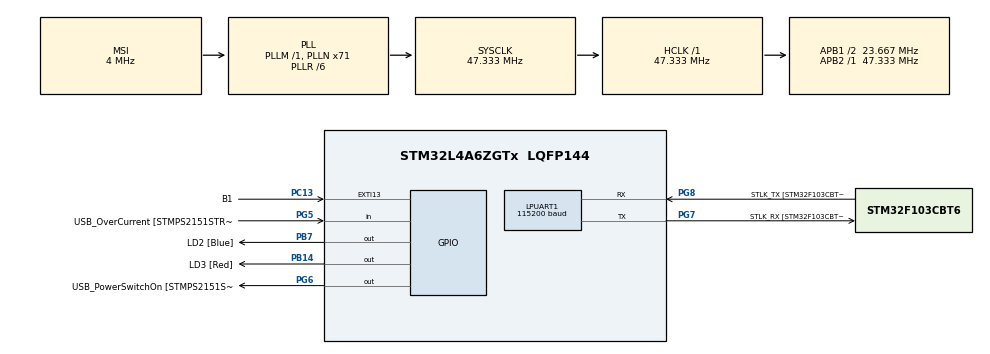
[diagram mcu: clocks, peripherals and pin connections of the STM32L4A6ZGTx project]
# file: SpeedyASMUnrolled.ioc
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LPUART1.AutoBaudRateEnableParam=UART_ADVFEATURE_AUTOBAUDRATE_DISABLE
LPUART1.BaudRate=115200
LPUART1.DMADisableonRxErrorParam=UART_ADVFEATURE_DMA_ENABLEONRXERROR
LPUART1.DataInvertParam=UART_ADVFEATURE_DATAINV_DISABLE
LPUART1.MSBFirstParam=UART_ADVFEATURE_MSBFIRST_DISABLE
LPUART1.Mode=UART_MODE_TX_RX
LPUART1.OneBitSampling=UART_ONE_BIT_SAMPLE_DISABLE
LPUART1.OverrunDisableParam=UART_ADVFEATURE_OVERRUN_ENABLE
LPUART1.Parity=UART_PARITY_NONE
LPUART1.RxPinLevelInvertParam=UART_ADVFEATURE_RXINV_DISABLE
LPUART1.StopBits=UART_STOPBITS_1
LPUART1.SwapParam=UART_ADVFEATURE_SWAP_DISABLE
LPUART1.TxPinLevelInvertParam=UART_ADVFEATURE_TXINV_DISABLE
LPUART1.WordLength=UART_WORDLENGTH_8B
Mcu.Family=STM32L4
Mcu.Name=STM32L4A6ZGTx
Mcu.Package=LQFP144
NVIC.PriorityGroup=NVIC_PRIORITYGROUP_4
PA10.GPIO_Label=USB_ID
PA10.Signal=USB_OTG_FS_ID
PA11.GPIO_Label=USB_DM
PA11.Signal=USB_OTG_FS_DM
PA12.GPIO_Label=USB_DP
PA12.Signal=USB_OTG_FS_DP
PA13\ (JTMS/SWDIO).GPIO_Label=TMS
PA13\ (JTMS/SWDIO).Mode=Trace_Asynchronous_SW
PA13\ (JTMS/SWDIO).Signal=SYS_JTMS-SWDIO
PA14\ (JTCK/SWCLK).GPIO_Label=TCK
PA14\ (JTCK/SWCLK).Mode=Trace_Asynchronous_SW
PA14\ (JTCK/SWCLK).Signal=SYS_JTCK-SWCLK
PA8.GPIO_Label=USB_SOF [TP1]
PA8.Signal=USB_OTG_FS_SOF
PA9.GPIO_Label=USB_VBUS
PA9.Signal=USB_OTG_FS_VBUS
PB14.GPIO_Label=LD3 [Red]
PB14.Signal=GPIO_Output
PB3\ (JTDO/TRACESWO).GPIO_Label=SWO
PB3\ (JTDO/TRACESWO).Mode=Trace_Asynchronous_SW
PB3\ (JTDO/TRACESWO).Signal=SYS_JTDO-SWO
PB7.GPIO_Label=LD2 [Blue]
PB7.Signal=GPIO_Output
PC13.GPIO_Label=B1
PC13.Signal=GPXTI13
PC14-OSC32_IN\ (PC14).Mode=LSE-External-Oscillator
PC14-OSC32_IN\ (PC14).Signal=RCC_OSC32_IN
PC15-OSC32_OUT\ (PC15).Mode=LSE-External-Oscillator
PC15-OSC32_OUT\ (PC15).Signal=RCC_OSC32_OUT
PG5.GPIO_Label=USB_OverCurrent [STMPS2151STR_FAULT]
PG5.Signal=GPIO_Input
PG6.GPIO_Label=USB_PowerSwitchOn [STMPS2151STR_EN]
PG6.Signal=GPIO_Output
PG7.GPIO_Label=STLK_RX [STM32F103CBT6_PA3]
PG7.Mode=Asynchronous
PG7.Signal=LPUART1_TX
PG8.GPIO_Label=STLK_TX [STM32F103CBT6_PA2]
PG8.Mode=Asynchronous
PG8.Signal=LPUART1_RX
PH1-OSC_OUT\ (PH1).Signal=RCC_OSC_OUT
ProjectManager.HeapSize=0x200
ProjectManager.StackSize=0x400
ProjectManager.TargetToolchain=STM32CubeIDE
RCC.ADCFreq_Value=48000000
RCC.AHBFreq_Value=47333333.333333336
RCC.APB1CLKDivider=RCC_HCLK_DIV2
RCC.APB1Freq_Value=23666666.666666668
RCC.APB1TimFreq_Value=47333333.333333336
RCC.APB2Freq_Value=47333333.333333336
RCC.APB2TimFreq_Value=47333333.333333336
RCC.CortexFreq_Value=47333333.333333336
RCC.FLatency=FLASH_LATENCY_2
RCC.HCLKFreq_Value=47333333.333333336
RCC.HSE_VALUE=8000000
RCC.HSI48_VALUE=48000000
RCC.HSI_VALUE=16000000
RCC.MSI_VALUE=4000000
RCC.PLLN=71
RCC.PLLR=RCC_PLLR_DIV6
RCC.PLLSAI1N=24
RCC.SYSCLKFreq_VALUE=47333333.333333336
RCC.SYSCLKSource=RCC_SYSCLKSOURCE_PLLCLK
RCC.USBFreq_Value=48000000
RCC.VCOOutputFreq_Value=284000000
board=NUCLEO-L4A6ZG

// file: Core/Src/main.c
/* USER CODE BEGIN Header */
/**
  ******************************************************************************
  * @file           : main.c
  * @brief          : Main program body
  ******************************************************************************
  * @attention
  *
  * <h2><center>&copy; Copyright (c) 2022 STMicroelectronics.
  * All rights reserved.</center></h2>
  *
  * This software component is licensed by ST under BSD 3-Clause license,
  * the "License"; You may not use this file except in compliance with the
  * License. You may obtain a copy of the License at:
  *                        opensource.org/licenses/BSD-3-Clause
  *
  ******************************************************************************
  */
/* USER CODE END Header */
#include "main.h"

/* USER CODE BEGIN Includes */
#include <inttypes.h>
#include <stdio.h>
/* USER CODE END Includes */

/* USER CODE BEGIN PD */
#define ARM_CM_DEMCR      (volatile uint32_t *)0xE000EDFC

#define ARM_CM_DWT_CYCCNT (volatile uint32_t *)0xE0001004

#define ARM_CM_DWT_CTRL   (volatile uint32_t *)0xE0001000

#define MAX_BUFF 110
/* USER CODE END PD */

UART_HandleTypeDef hlpuart1;

void SystemClock_Config(void);
static void MX_GPIO_Init(void);
static void MX_LPUART1_UART_Init(void);
/* USER CODE BEGIN PFP */
void serial_out(char *label, uint8_t *dat0, uint8_t *dat1, uint8_t *dat2, uint8_t *dat3, uint8_t *dat4, uint8_t *dat5, int *i);

/* USER CODE END PFP */

/* USER CODE BEGIN 0 */
uint32_t startB, stopB, startE, stopE;
int deltaE = 0;
int deltaB = 0;
/* USER CODE END 0 */

int main(void)
{
  /* USER CODE BEGIN 1 */
  *ARM_CM_DEMCR     =  (*ARM_CM_DEMCR) | 0x01000000;  // Set bit 24
  *ARM_CM_DWT_CTRL = (*ARM_CM_DWT_CTRL) | 0x00000001 ;
  /* USER CODE END 1 */

  /* MCU Configuration--------------------------------------------------------*/

  /* Reset of all peripherals, Initializes the Flash interface and the Systick. */
  HAL_Init();

  /* Configure the system clock */
  SystemClock_Config();

  /* Initialize all configured peripherals */
  MX_GPIO_Init();
  MX_LPUART1_UART_Init();
  /* USER CODE BEGIN 2 */

  uint32_t Plaintext[6] = {0xA13A6324, 0x51070E43, 0x82A27F26, 0xA40682F3, 0xFE9FF680, 0x28D24FDB};
  /*All the keys are in bitslice representation */
  uint32_t Keys[8][6] = {{0X65CB7895, 0XAA4CAA9B, 0X98F8709C, 0XD4C43B89, 0X12C93259, 0XB7C604AB},		//k[0]	//master key
   					     {0x88FFA82A, 0x4F47C286, 0x5568A336, 0x8CA19C61, 0x0FCF3328, 0x3C774987},		//k[1]
   					     {0X61B1B178, 0X992302FD, 0X25B26492, 0X062BDD4D, 0XC27DB705, 0X66AB3AA8},		//k[2]
   					     {0XEEC40279, 0X4339C318, 0X37144EDA, 0X4E39AED2, 0X22AAA1FE, 0X1B1F1D28},		//k[3]
   					     {0X4B24C964, 0X12AEDF18, 0X2E5BC4AB, 0X54DD5265, 0XC7C384E4, 0XDC4EA621},		//k[4]
   					     {0X3F3CCCA0, 0X261CF1DD, 0X47FD4154, 0X14327A3E, 0XAB4519B2, 0XE30C650C},		//k[5]
   					     {0X09F6DC17, 0XEAA19AAC, 0X0D8D8BC3, 0X17ECC918, 0X2D932491, 0XEA68315E},		//k[6]
   					     {0X8AAA87F8, 0X74A06C7C, 0X762013CF, 0X18C219CE, 0XB8A276D1, 0X769271CD} };	//k[7]	//final key

  serial_out("Speedy encryption begin using bitslice and ASM", NULL, NULL, NULL, NULL, NULL, NULL, NULL);
  serial_out("Plaintext[0] = ", (uint8_t*)&Plaintext[0], (uint8_t*)&Plaintext[1], (uint8_t*)&Plaintext[2], (uint8_t*)&Plaintext[3], (uint8_t*)&Plaintext[4], (uint8_t*)&Plaintext[5], NULL);
  serial_out("Key = ", (uint8_t*)&Keys[0][0], (uint8_t*)&Keys[0][1], (uint8_t*)&Keys[0][2], (uint8_t*)&Keys[0][3], (uint8_t*)&Keys[0][4], (uint8_t*)&Keys[0][5], NULL);

  *ARM_CM_DWT_CYCCNT = 0;
  startB = *ARM_CM_DWT_CYCCNT;

  asm(	/*Load plaintext from stack to registers r0 - r5*/
		"ldr r0, [sp, #192];"				//load the first 32 bits i.e. Plaintext[0]
  		"ldr r1, [sp, #196];"				//load Plaintext[1]
  		"ldr r2, [sp, #200];"				//load Plaintext[2]
  		"ldr r3, [sp, #204];"				//load Plaintext[3]
  		"ldr r4, [sp, #208];"				//load Plaintext[4]
  		"ldr r5, [sp, #212];"				//load Plaintext[5]
  		"mov r12, 0x0000;"					//mask lower 16 bits
  		"movt r12, 0xFC00;"					//mask upper 16 bits
    );

    asm(	/*	convert plaintext to bitslice  */
  		//  here is to change b10 b11 b12 b13 b14 b15 for b60 b61 b62 b63 b64 b65
  		"lsl r6, r1, #4;"		  			// r6 <= (b << 4)   temporary
  		"eor r7, r6, r0, lsl #6;"  			// r7 <= (b << 4) xor (a << 6) temporary

  		"and r8 , r7, r12;"		  			// r8 => T <= ((b << 4) xor (a << 6)) ^ (M)
  		"eor r1, r1, r8, lsr #4;" 			// r1 <= (r1 xor (T >> 4));  //B = B xor (T >> 4);
  		"eor r0, r0, r8, lsr #6;" 			// r0 <= (r0 xor (T >> 6));  //A = A xor (T >> 6);

  		// end of swap move for block 1 with block 6
  		//	swap b120b121b122b123b124b125 with b20b21b22b23b24b25

  		"eor r6, r2, r0, lsl #4;"			// r2 xor (r0 << 4) align blk2 with blk12 and performs xor operation
  		"and r6, r6, r12, lsr #8;"			// r6 = (r2 xor (r0 << 4)) ^ r12	r2 => 00FC0000

  		"eor r2, r2, r6;"					// r2 = r2 xor T
  		"eor r0, r0, r6, lsr #4;"			// r0 = r0 xor (T >> 4)

  		// end swap
  		//swap b30b31b32b33b34b35 in r0 with b180b181b182b183b184b185 in r3

  		"eor r6, r3, r0, lsl #6;"			// r3 xor (r0 << 6) align blk3 with blk18 and performs xor operation
  		"and r6, r6, r12, lsr #12;" 		// r6 = (r3 xor (r0 << 6)) ^ r12	r12 => 000FC000

  		"eor r3, r3, r6;"					// r3 = r3 xor T
  		"eor r0, r0, r6, lsr #6;"			// r0 = r0 xor (T >> 6)

  		//end swap
  		//swap b40b41b42b43b44b45 in r0 with b240b241b242b243b244b25 in r4

  		"eor r6, r4, r0, lsl #8;"			// r4 xor (r0 << 8) align blk4 with blk 24 and performs xor operation
  		"and r6, r6, r12, lsr #16;"			// r6 = (r4 xor (r0 << 8)) ^ r12		r12 => 0000FC00

  		"eor r4, r4, r6;"					// r4 = r4 xor T
  		"eor r0, r0, r6, lsr #8;"			// r0 = r0 xor (T >> 8)
  		//end swap
  		//rotate register r1, r2, r3, r4 to align block b0,b1,b2,b3,b4
  		"ror r1, r1, #28;"					// rotate register r1 to align the bits b10b11b12b13b14b15 with b00b01b02b03b04b05
  		"ror r2, r2, #24;"					// rotate register r2 to align the bits b20b21b22b23b24b25 with b10b11b12b13b14b15
  		"ror r3, r3, #20;"					// rotate register r3 to align the bits b30b31b32b33b34b35 with b20b21b22b23b24b25
  		"ror r4, r4, #16;"					// rotate register r4 to align the bits b40b41b42b43b44b45 with b30b31b32b33b34b35
  		//End rotation
  		//	swap blocks
  		//swap b80b81b82b83b84b85 in r1 with b130b131b132b133b134b135 in r2
  		"eor r6, r2, r1, lsl #6;"			// r2 xor (r1 << 6) align blk8 with blk13 and performs xor operation
  		"and r6, r6, r12, lsr #6;"			// r6 = (r2 xor (r1 << 6)) ^ r12		r12 => 0x03F00000

  		"eor r2, r2, r6;"					// r2 = r2 xor T
  		"eor r1, r1, r6, lsr #6;"			// r0 = r0 xor (T >> 6)
  		//end swap

  		//swap b90b91b92b93b94b95 in r1 with b190b191b192b193b194b195 in r3
  		"eor r6, r3, r1, lsl #12;"			// r3 xor (r1 << 12) align blk9 wit block19 and performs xor operation
  		"and r6, r6, r12, lsr #6;"			// r6 = (r2 xor (r1 << 12)) ^ r12		r12 => 0x03F00000

  		"eor r3, r3, r6;"					// r3 = r3 xor T
  		"eor r1, r1, r6, lsr #12;"			// r1 = r1 xor (T >> 12)
  		//end swap

  		//swap b150b151b152b153b154b155 in r2 with b200b201b202b203b204b205 in r3
  		"eor r6, r3, r2, lsl #6;"			// r3 xor (r2 << 6) align blk15 with blk20 and performs xor operation
  		"and r6, r6, r12, lsr #12;"			// r6 = (r3 xor (r2 << 6)) ^ r12 		r12 => 0x00068000

  		"eor r3, r3, r6;"					// r3 = r3 xor T
  		"eor r2, r2, r6, lsr #6;"			// r2 = r2 xor (T >> 6)

  		//move blocks 5, 10, 21, 26 to register r11 and puts zeroes in their places

  		"mov r11, r0, lsl #30;"				// move bits b50b51 to register r11 temporary
  		"and r10, r1, 0x0000000F;"			// move bits b52b53b54b55 to register 10 temporary
  		"eor r11, r11, r10, lsl #26;" 		// join bits b50b51b52b53b54b55 into registry r11

  		"and r10, r1, 0x000000F0;"			// move bits b100b101b102b103
  		"eor r11, r11, r10, lsl #18;"		// join bits b100b101b102b103 to reg11

  		"and r10, r2, 0x000000C0;"			// move bits b104b105 to reg10
  		"eor r11, r11, r10, lsl #14;"		// join bits b100b101b102b103 with b104b105

  		"and r10, r3, 0x00003000;"			// move bits b210b211 to r10
  		"eor r11, r11, r10, lsl #6;"		// join bits b210b211 wit previous bits in r11

  		"and r10, r4, 0xF000;"				//
  		"eor r11, r11, r10, lsl #2;"		//

  		"and r10, r4, 0x000F0000;"			//
  		"eor r11, r11, r10, lsr #6;"		//

  		"and r10, r5, 0xC0000000;"			//
  		"eor r11, r11, r10, lsr #22;"		//

  		"and r0, r0, 0xFFFFFFFC;"			//clear bits b50b51
  		"and r1, r1, 0xFFFFFF00;"			//clear bits b100b101b102b103 b52b53b54b55
  		"and r2, r2, 0xFFFFFF3F;"			//clear bits b104b105
  		"and r3, r3, 0xFFFFCFFF;"			//clear bits b210b211
  		"and r4, r4, 0xFFF00FFF;"			//clear bits b260b261b262b263 b212b213b214b215
  		"and r5, r5, 0x3FFFFFFF;"			//clear bits b264b265

  		//rotate r5 to align all blocks and send the 00 to the end of the register
  		"ror r5, r5, #30;"					//move b264b265 in 00 to the ond of register

  		//swap b250b251b252b253b254b255 with 000000 in r0 aligned with b240b241b242b243b244b245
  		"and r6, r12, r4, lsl #6;"			//save blk25 stored r4 to r6

  		"eor r4, r4, r6, lsr #6;"			//put zeroes in blk25 position
  		"eor r1, r1, r6, lsr #24;"			//move move blk25 to its position in r1

  		"eor r6, r5, r11;"					//xor blk27 with blk5
  		"and r6, r6, r12;"					//r6 = (blk5 xor blk27) ^ r12 	r12=>0xFC000000
  		"eor r5, r5, r6;"					//put blk5 in r5
  		"eor r11, r11, r6;"					//put blk27 in r11

  		"eor r6, r4, r11;"					//xor blk10 in r11 with 0's in r4
  		"and r6, r6, r12, lsr #6;"			//r6 = (r4 xor r11) ^ r12		r12 >> 6 => 0x03F00000
  		"eor r4, r4, r6;"					//put blk10 in r4 in it's position
  		"eor r11, r11, r6;"					//put 0's in r11 replacing place of blk10

  		"eor r6, r5, r11;"					//xor blk28 in r5 with 0's in r11
  		"and r6, r6, r12, lsr #6;"			//r6 = (r5 xor r11) ^ r12		r12 >> 6 => 0x03F00000
  		"eor r5, r5, r6;"					//put 0's in r5 in place on blk28
  		"eor r11, r11, r6;"					//put blk28 in r11 in place of 0's

  		"eor r6, r5, r2, lsl #20;"			//xor blk11 with 0's in r5
  		"and r6, r6, r12, lsr #6;"			//r6 = (r2 xor r5) ^ r12		r12 >> 6 => 0x03F00000
  		"eor r5, r5, r6;"					//put blk11 in it's place in r5
  		"eor r2, r2, r6, lsr #20;"			//put 0's in place of blk11

  		"and r6, r3, r12, lsr #20;"			//get blk16 from r3
  		"eor r4, r4, r6, lsl #8;"			//put bll16 in r4 and get aligned with blk15
  		"eor r3, r3, r6;"					//clean blk16 in r3

  		"and r6, r11, r12, lsr #12;"		//bet blk21 from r11
  		"eor r3, r3, r6, lsr #6;"			//put blk21 in r3
  		"eor r11, r11, r6;"					//clean blk211 from r11

  		"and r6, r11, r12, lsr #18;"		//get blk26 from r11
  		"eor r2, r2, r6, lsr #6;"			//put blk26 in r2 aligned with blk25 in r1
  		"eor r11, r11, r6;"					// clear blk26 from r11

  		"mov  r12, 0xFFFC;"					//new mask
  		"movt r12, 0x000F;"					//new mask

  		"and r6, r5, r12;"					//get blk29, blk30, blk31 from r5
  		"eor r5, r5, r6;"					//clean blk29, blk30, blk31 in r5
  		"eor r11, r11, r6;"					//put blk29,blk30,blk31 in r11;

  		"mov r12, 0x0000;"					//put mask on r12
  		"movt r12, 0xFC00;"					//put mask on r12

  		"and r6, r3, r12, lsr #26;"			//get blk17 bits with the mask to r6 as temporary reg
  		"eor r3, r3, r6;"					//clear r3 blk17 bits in r3
  		"eor r5, r5, r6, lsl #14;"			//put blk17 bits in its position in r6 aligned with r16

  		"and r6, r4, r12, lsr #20;"			//get blk22 from r4
  		"eor r4, r4, r6;"					//clear blk22 from r4
  		"eor r4, r4, r6, lsl #2;"			//paste blk22 to r4 just moving the two places to the left

  		"and r6, r4, r12, lsr #26;"			//get blk23 from r4
  		"eor r4, r4, r6;"					//clear blk23 from r4
  		"eor r5, r5, r6, lsl #8;"			//put blk23 to r5 aligned to blk22 in r4

  		//move blks 27, 28, 29 to r3, r4, r5 respectively

  		"and r6, r11, r12;"					//get blk27 from r11
  		"eor r11, r11, r6;"					//clear blk27 from r11
  		"eor r3, r3, r6, lsr #24;"			//put blk27 in r3 and get aligned with blk26

  		"and r6, r11, r12, lsr #6;"			//get blk28 from r11
  		"eor r11, r11, r6;"					//clear blk28 from r11
  		"eor r4, r4, r6, lsr #18;"			//put blk28 in r4 and get aligned with blk27 in r3

  		"and r6, r11, r12, lsr #12;"		//get blk29 from r11
  		"eor r11, r11, r6;"					//clear blk29 from r11
  		"eor r5, r5, r6, lsr #12;"			//put blk29 in r5 and get aligned with blk28 in r4

  		// move the last blks30 and blk31 in bit pairs

  		"mov r12, 0x2000;"					//mask of 1 bit

  		"and r6, r11, r12;"					//get b300 from r11
  		"eor r0, r0, r6, lsr #12;"			//put b300 in r0 position 30

  		"and r6, r11, r12, lsr #1;"			//get b301 from r11
  		"eor r1, r1, r6, lsr #11;"			//put b301 in r1 position 30

  		"and r6, r11, r12, lsr #2;"			//get b302 from r11
  		"eor r2, r2, r6, lsr #10;"			//put b302 in r2 position 30

  		"and r6, r11, r12, lsr #3;"			//get b303 from r11
  		"eor r3, r3, r6, lsr #9;"			//put b303 in r3 position 30

  		"and r6, r11, r12, lsr #4;"			//get b304 from r11
  		"eor r4, r4, r6, lsr #8;"			//put b304 in r4 position 30

  		"and r6, r11, r12, lsr #5;"			//get b305 from r11
  		"eor r5, r5, r6, lsr #7;"			//put b305 in r5 position 30

  		/*		blk31		*/

  		"and r6, r11, r12, lsr #6;"			//get b310 from r11
  		"eor r0, r0, r6, lsr #7;"			//put b310 in r0 position 31

  		"and r6, r11, r12, lsr #7;"			//get b311 from r11
  		"eor r1, r1, r6, lsr #6;"			//put b311 in r1 position 31

  		"and r6, r11, r12, lsr #8;"			//get b312 from r11
  		"eor r2, r2, r6, lsr #5;"			//put b312 in r2 position 31

  		"and r6, r11, r12, lsr #9;"			//get b313 from r11
  		"eor r3, r3, r6, lsr #4;"			//put g313 in r3 position 31

  		"and r6, r11, r12, lsr #10;"		//get b314 from r11
  		"eor r4, r4, r6, lsr #3;"			//put b314 in r4 position 31

  		"and r6, r11, r12, lsr #11;"		//get b315 from r11
  		"eor r5, r5, r6, lsr #2;"			//put b315 in r5 position 31

  		"eor r6, r6, r6;"					//clear r6 registry
  		"eor r11, r11, r11;"				//clear r11 registry
  		"eor r12, r12, r12;"				//clear r12 registry

  	/*		Final step for bitslice representation		*/

  		"mov r12,  0x2080;"					//mask low part
  		"movt r12, 0x8208;"					//mask high part

  		"eor r6, r1, r0, lsl #1;"			//recover the b1 from all 5 blks in r0 i.e. blk01, blk61, blk121, blk181, blk241, and make a xor with r1 blk10, blk70, blk131, blk190, blk250
  		"and r6, r6, r12;"					//just get the bit b0 from all blks xored here
  		"eor r1, r1, r6;"					//put bx1's bits in bx0's place in r1
  		"eor r0, r0, r6, lsr #1;"			//put bx0's bits in bx1's place in r0

  		"eor r6, r2, r0, lsl #2;"			//xor r2 with (r0 << 2)			r6 <= r2 ^ (r0 << 2)
  		"and r6, r6, r12;"					//get the bits b0 xor b1 here
  		"eor r2, r2, r6;"					//paste blkx2's bits in r2 b0 place
  		"eor r0, r0, r6, lsr #2;"			//paste blkx0's bits in r0 b2 place

  		"eor r6, r3, r0, lsl #3;"
  		"and r6, r6, r12;"
  		"eor r3, r3, r6;"
  		"eor r0, r0, r6, lsr #3;"

  		"eor r6, r4, r0, lsl #4;"
  		"and r6, r6, r12;"
  		"eor r4, r4, r6;"
  		"eor r0, r0, r6, lsr #4;"

  		"eor r6, r5, r0, lsl #5;"
  		"and r6, r6, r12;"
  		"eor r5, r5, r6;"
  		"eor r0, r0, r6, lsr #5;"

  		"ror r12, r12, #1;"					//rotate to the right the mask to get one place to the right

  		"eor r6, r2, r1, lsl #1;"
  		"and r6, r6, r12;"
  		"eor r2, r2, r6;"
  		"eor r1, r1, r6, lsr #1;"

  		"eor r6, r3, r1, lsl #2;"
  		"and r6, r6, r12;"
  		"eor r3, r3, r6;"
  		"eor r1, r1, r6, lsr #2;"

  		"eor r6, r4, r1, lsl #3;"
  		"and r6, r6, r12;"
  		"eor r4, r4, r6;"
  		"eor r1, r1, r6, lsr #3;"

  		"eor r6, r5, r1, lsl #4;"
  		"and r6, r6, r12;"
  		"eor r5, r5, r6;"
  		"eor r1, r1, r6, lsr #4;"

  		"ror r12, r12, #1;"					//rotate to the right the mask to get one place to the right

  		"eor r6, r3, r2, lsl #1;"
  		"and r6, r6, r12;"
  		"eor r3, r3, r6;"
  		"eor r2, r2, r6, lsr #1;"

  		"eor r6, r4, r2, lsl #2;"
  		"and r6, r6, r12;"
  		"eor r4, r4, r6;"
  		"eor r2, r2, r6, lsr #2;"

  		"eor r6, r5, r2, lsl #3;"
  		"and r6, r6, r12;"
  		"eor r5, r5, r6;"
  		"eor r2, r2, r6, lsr #3;"

  		"ror r12, r12, #1;"					//rotate to the right the mask to get one place to the right

  		"eor r6, r4, r3, lsl #1;"
  		"and r6, r6, r12;"
  		"eor r4, r4, r6;"
  		"eor r3, r3, r6, lsr #1;"

  		"eor r6, r5, r3, lsl #2;"
  		"and r6, r6, r12;"
  		"eor r5, r5, r6;"
  		"eor r3, r3, r6, lsr #2;"

  		"ror r12, r12, #1;"					//rotate to the right the mask to get on place to the right

  		"eor r6, r5, r4, lsl #1;"
  		"and r6, r6, r12;"
  		"eor r5, r5, r6;"
  		"eor r4, r4, r6, lsr #1;"
  		/* Bitslice conversion end*/
  	);

    stopB  = *ARM_CM_DWT_CYCCNT;
    deltaB = stopB - startB;

    *ARM_CM_DWT_CYCCNT = 0;
    startE = *ARM_CM_DWT_CYCCNT;

  ///////////// round  0 //////////////
  	asm(/*	ARK	 the key 0 must be in bitslice*/
  		"ldr r6, [sp, #0];"					//load bitslice key [0]  only bits "b_0"
  		"ldr r7, [sp, #4];"					//load bitslice key [0]  only bits "b_1"
  		"ldr r8, [sp, #8];"					//load bitslice key [0]  only bits "b_2"
  		"ldr r9, [sp, #12];"				//load bitslice key [0]  only bits "b_3"
  		"ldr r10, [sp, #16];"				//load bitslice key [0]  only bits "b_4"
  		"ldr r11, [sp, #20];"				//load bitslice key [0]  only bits "b_5"
  		/* XOR each register with the key position bit*/
  		"eor r0, r0, r6;"
  		"eor r1, r1, r7;"
  		"eor r2, r2, r8;"
  		"eor r3, r3, r9;"
  		"eor r4, r4, r10;"
  		"eor r5, r5, r11;"
  		/*END of ARK*/
  	);

  	asm(	/*		Sbox implementation in assembly		*/
  		"and r9, r4, r2;"					//  r9  <= r2 and r4
  		"orn r9, r9, r5;"					//  r9  <= not((r2 and r4) or r5)
  		"and r9, r9, r3;"					//	r9  <= r3 and not((r2 and r4) or r5)
  		"and r10, r5, r4;"					//	r10 <= (r5 and r4)
  		"orn r11, r3, r0;"					//	r11 <= not(r3 or r0)
  		"orn r10, r10, r11;"				//	r10 <= not((r5 and r4) or (not(r3 or r0)))
  		"and r10, r1, r10;"					//	r10 <= (not((r5 and r4) or (not(r3 or r0)))) and (r1)
  		"orr r6, r10, r9;"					//	r6  <= (((not((r5 and r4) or (not(r3 or r0)))) and (r1)) or (r3 and not((r2 and r4) or r5)))

  		"and r9, r0, r2;"					//	r9  <= (r0 and r2)			r9 	overwrite
  		"orn r10, r2, r3;"					//	r10 <= not(r2 or r3)		r10 overwrite
  		"orn r9, r9, r10;"					//	r9	<= not((r0 and r0) or (not(r2 or r3)))
  		"and r9, r9, r5;"					//	r9	<= ((not((r0 and r0) or (not(r2 or r3)))) and r5)
  		"orr r10, r5, r4;"					//	r10 <= (r5 or r4)			r10 overwrite
  		"orn r10, r10, r3;"					//	r10 <= not((not(r5 or r4)) or r3)
  		"orn r9, r9, r10;"					//	r9 	<= not(((not((r0 and r0) or (not(r2 or r3)))) and r5) or (not((not(r5 or r4)) or r3)))
  		"orr r10, r0, r3;"					//	r10 <= (r0 or r3)			r10	overwrite
  		"orn r10, r10, r1;"					//	r10	<= not((r0 or r3) or r1)
  		"orn r7, r9, r10;"					//	r7	<= not((not(((not((r0 and r0) or (not(r2 or r3)))) and r5) or (not((not(r5 or r4)) or r3)))) or (not((r0 or r3) or r1)) )

  		"and r9, r1, r3;"					//	r9 	<= (r1 and r3)			r9	overwrite
  		"orn r10, r3, r4;"					//	r10 <= not(r3 or r4)		r10	overwrite
  		"orn r9, r9, r10;"					//	r9	<= not((not(r3 or r4)) or (r1 and r3))
  		"and r9, r0, r9;"					//	r9	<= ((not((not(r3 or r4)) or (r1 and r3))) and r0)
  		"orr r10, r3, r4;"					//	r10 <= (r3 or r4)			r10	overwrite
  		"orn r10, r10, r2;"					//	r10	<= not((r3 or r4) or r2)
  		"orn r9, r9, r10;"					//	r9	<= not(((not((not(r3 or r4)) or (r1 and r3))) and r0) or (not((r3 or r4) or r2)) )
  		"orr r10, r0, r2;"					//	r10	<= (r0 or r2)			r10	overwrite
  		"orr r10, r10, r5;"					//	r10 <= ((r0 or r2) or r5)
  		"orn r8, r9, r10;"					//	r8	<= not((not(((not((not(r3 or r4)) or (r1 and r3))) and r0) or (not((r3 or r4) or r2)))) or (((r0 or r2) or r5)))

  		"and r9, r0, r4;"					//	r9	<= (r0 and r4)			r9	overwrite
  		"orr r10, r0, r3;"					//	r10	<= (r0 or r3)			r10 overwrite
  		"orn r9, r9, r10;"					//	r9	<= not((r0 and r4) or (r0 or r3))
  		"and r9, r9, r2;"					//	r9	<= ((not((r0 and r4) or (r0 or r3))) and r2)
  		"and r10, r0, r5;"					//	r10 <= (r0 and r5)			r10	overwrite
  		"orn r10, r2, r10;"					//	r10	<= not((r0 and r5) or r2)
  		"orn r9, r9, r10;"					//	r9	<= not(((not((r0 and r4) or (r0 or r3))) and r2) or (not((r0 and r5) or r2)))
  		"and r10, r1, r3;"					//	r10 <= (r1 and r3)			r10 overwrite
  		"orn r10, r0, r10;"					//	r10	<= not((r1 and r3) or r0)
  		"orn r9, r9, r10;"					//	r9	<= not((not(((not((r0 and r4) or (r0 or r3))) and r2) or (not((r0 and r5) or r2)))) or (not((r1 and r3) or r0)))

  		"eor r12, r12, r12;" 	    	  	//  put 0's to the reg 12

  		"orr r10, r4, r2;"					//	r10	<= (r4 or r2)
  		"orr r11, r0, r1;"					//	r11 <= (r0 or r1)
  		"orn r10, r10, r11;"				//	r10	<= not((r4 or r2) or (r0 or r1))
  		"orn r10, r12, r10;"				//	r10	<= not(() or (not((r4 or r2) or (r0 or r1))))
  		"orn r11, r3, r0;"					//	r11	<= not( r3 or r0)		r11	overwrite
  		"orn r10, r10, r11;"				//	r10	<= not((not(() or (not((r4 or r2) or (r0 or r1))))) or (not( r3 or r0)))
  		"and r11, r4, r5;"					//	r11	<= (r4 and r5)			r11	overwrite
  		"orn r11, r0, r11;"					//	r11 <= not((r4 and r5) or r0)
  		"orn r10, r10, r11;"				//	r10 <= not((not((not(() or (not((r4 or r2) or (r0 or r1))))) or (not( r3 or r0)))) or (not((r4 and r5) or r0)))

  		"and r12, r0, r3;"					//  r12 <= (r0 and r3)			r12	overwrite
  		"orn r11, r2, r4;"					//	r11	<= not(r2 or r4)		r11	overwrite
  		"orn r12, r12, r11;"				//	r12	<= not(((r0 and r3)) or (not(r2 or r4)))
  		"orn r12, r1, r12;"					//	r12	<= not((not(((r0 and r3)) or (not(r2 or r4)))) or r1)
  		"and r11, r1, r0;"					//	r11	<= (r1 and r0)
  		"orr r11, r11, r5;"					//	r11	<= ((r1 and r0) or r5)
  		"and r11, r11, r2;"					//	r11	<= (((r1 and r0) or r5) and r2)
  		"orn r11, r11, r12;"				//	r11	<= not((((r1 and r0) or r5) and r2) or (not((not(((r0 and r3)) or (not(r2 or r4)))) or r1)))
  		/*		Sbox implementation assembly end	*/
  	);

  	asm(	/* shift columns */
  		"mov r0, r6;"
  		"mov r1, r7, ror #31;"
  		"mov r2, r8, ror #30;"
  		"mov r3, r9, ror #29;"
  		"mov r4, r10, ror #28;"
  		"mov r5, r11, ror #27;"
  		/* shift columns end */
  	);

  	asm(	/*		Sbox implementation in assembly		*/
  		"and r9, r4, r2;"					//  r9  <= r2 and r4
  		"orn r9, r9, r5;"					//  r9  <= not((r2 and r4) or r5)
  		"and r9, r9, r3;"					//	r9  <= r3 and not((r2 and r4) or r5)
  		"and r10, r5, r4;"					//	r10 <= (r5 and r4)
  		"orn r11, r3, r0;"					//	r11 <= not(r3 or r0)
  		"orn r10, r10, r11;"				//	r10 <= not((r5 and r4) or (not(r3 or r0)))
  		"and r10, r1, r10;"					//	r10 <= (not((r5 and r4) or (not(r3 or r0)))) and (r1)
  		"orr r6, r10, r9;"					//	r6  <= (((not((r5 and r4) or (not(r3 or r0)))) and (r1)) or (r3 and not((r2 and r4) or r5)))

  		"and r9, r0, r2;"					//	r9  <= (r0 and r2)			r9 	overwrite
  		"orn r10, r2, r3;"					//	r10 <= not(r2 or r3)		r10 overwrite
  		"orn r9, r9, r10;"					//	r9	<= not((r0 and r0) or (not(r2 or r3)))
  		"and r9, r9, r5;"					//	r9	<= ((not((r0 and r0) or (not(r2 or r3)))) and r5)
  		"orr r10, r5, r4;"					//	r10 <= (r5 or r4)			r10 overwrite
  		"orn r10, r10, r3;"					//	r10 <= not((not(r5 or r4)) or r3)
  		"orn r9, r9, r10;"					//	r9 	<= not(((not((r0 and r0) or (not(r2 or r3)))) and r5) or (not((not(r5 or r4)) or r3)))
  		"orr r10, r0, r3;"					//	r10 <= (r0 or r3)			r10	overwrite
  		"orn r10, r10, r1;"					//	r10	<= not((r0 or r3) or r1)
  		"orn r7, r9, r10;"					//	r7	<= not((not(((not((r0 and r0) or (not(r2 or r3)))) and r5) or (not((not(r5 or r4)) or r3)))) or (not((r0 or r3) or r1)) )

  		"and r9, r1, r3;"					//	r9 	<= (r1 and r3)			r9	overwrite
  		"orn r10, r3, r4;"					//	r10 <= not(r3 or r4)		r10	overwrite
  		"orn r9, r9, r10;"					//	r9	<= not((not(r3 or r4)) or (r1 and r3))
  		"and r9, r0, r9;"					//	r9	<= ((not((not(r3 or r4)) or (r1 and r3))) and r0)
  		"orr r10, r3, r4;"					//	r10 <= (r3 or r4)			r10	overwrite
  		"orn r10, r10, r2;"					//	r10	<= not((r3 or r4) or r2)
  		"orn r9, r9, r10;"					//	r9	<= not(((not((not(r3 or r4)) or (r1 and r3))) and r0) or (not((r3 or r4) or r2)) )
  		"orr r10, r0, r2;"					//	r10	<= (r0 or r2)			r10	overwrite
  		"orr r10, r10, r5;"					//	r10 <= ((r0 or r2) or r5)
  		"orn r8, r9, r10;"					//	r8	<= not((not(((not((not(r3 or r4)) or (r1 and r3))) and r0) or (not((r3 or r4) or r2)))) or (((r0 or r2) or r5)))

  		"and r9, r0, r4;"					//	r9	<= (r0 and r4)			r9	overwrite
  		"orr r10, r0, r3;"					//	r10	<= (r0 or r3)			r10 overwrite
  		"orn r9, r9, r10;"					//	r9	<= not((r0 and r4) or (r0 or r3))
  		"and r9, r9, r2;"					//	r9	<= ((not((r0 and r4) or (r0 or r3))) and r2)
  		"and r10, r0, r5;"					//	r10 <= (r0 and r5)			r10	overwrite
  		"orn r10, r2, r10;"					//	r10	<= not((r0 and r5) or r2)
  		"orn r9, r9, r10;"					//	r9	<= not(((not((r0 and r4) or (r0 or r3))) and r2) or (not((r0 and r5) or r2)))
  		"and r10, r1, r3;"					//	r10 <= (r1 and r3)			r10 overwrite
  		"orn r10, r0, r10;"					//	r10	<= not((r1 and r3) or r0)
  		"orn r9, r9, r10;"					//	r9	<= not((not(((not((r0 and r4) or (r0 or r3))) and r2) or (not((r0 and r5) or r2)))) or (not((r1 and r3) or r0)))

  		"eor r12, r12, r12;"  			   	// r12 <= 0's

  		"orr r10, r4, r2;"					//	r10	<= (r4 or r2)
  		"orr r11, r0, r1;"					//	r11 <= (r0 or r1)
  		"orn r10, r10, r11;"				//	r10	<= not((r4 or r2) or (r0 or r1))
  		"orn r10, r12, r10;"				//	r10	<= not(() or (not((r4 or r2) or (r0 or r1))))
  		"orn r11, r3, r0;"					//	r11	<= not( r3 or r0)		r11	overwrite
  		"orn r10, r10, r11;"				//	r10	<= not((not(() or (not((r4 or r2) or (r0 or r1))))) or (not( r3 or r0)))
  		"and r11, r4, r5;"					//	r11	<= (r4 and r5)			r11	overwrite
  		"orn r11, r0, r11;"					//	r11 <= not((r4 and r5) or r0)
  		"orn r10, r10, r11;"				//	r10 <= not((not((not(() or (not((r4 or r2) or (r0 or r1))))) or (not( r3 or r0)))) or (not((r4 and r5) or r0)))

  		"and r12, r0, r3;"					//  r12 <= (r0 and r3)			r12	overwrite
  		"orn r11, r2, r4;"					//	r11	<= not(r2 or r4)		r11	overwrite
  		"orn r12, r12, r11;"				//	r12	<= not(((r0 and r3)) or (not(r2 or r4)))
  		"orn r12, r1, r12;"					//	r12	<= not((not(((r0 and r3)) or (not(r2 or r4)))) or r1)
  		"and r11, r1, r0;"					//	r11	<= (r1 and r0)
  		"orr r11, r11, r5;"					//	r11	<= ((r1 and r0) or r5)
  		"and r11, r11, r2;"					//	r11	<= (((r1 and r0) or r5) and r2)
  		"orn r11, r11, r12;"				//	r11	<= not((((r1 and r0) or r5) and r2) or (not((not(((r0 and r3)) or (not(r2 or r4)))) or r1)))
  		/*		Sbox implementation assembly end	*/
  	);

  	asm(	/* shift columns */
  		"mov r0, r6;"
  		"mov r1, r7, ror #31;"
  		"mov r2, r8, ror #30;"
  		"mov r3, r9, ror #29;"
  		"mov r4, r10, ror #28;"
  		"mov r5, r11, ror #27;"
  		/* shift columns end */
  	);

  	asm(	/* mix columns*/
  		"eor r0, r0, r6, ror #31;" 			//here the mix columns for the r0 register is calculated
  		"eor r0, r0, r6, ror #27;"
  		"eor r0, r0, r6, ror #23;"
  		"eor r0, r0, r6, ror #17;"
  		"eor r0, r0, r6, ror #11;"
  		"eor r0, r0, r6, ror #6;"

  		"eor r1, r1, r7, ror #30;"			//mix columns for the r1 register is calculated
  		"eor r1, r1, r7, ror #26;"
  		"eor r1, r1, r7, ror #22;"
  		"eor r1, r1, r7, ror #16;"
  		"eor r1, r1, r7, ror #10;"
  		"eor r1, r1, r7, ror #5;"

  		"eor r2, r2, r8, ror #29;"			//mix columns for the r2 register is calculated
  		"eor r2, r2, r8, ror #25;"
  		"eor r2, r2, r8, ror #21;"
  		"eor r2, r2, r8, ror #15;"
  		"eor r2, r2, r8, ror #9;"
  		"eor r2, r2, r8, ror #4;"

  		"eor r3, r3, r9, ror #28;"			//mix columns for the r3 register is calculated
  		"eor r3, r3, r9, ror #24;"
  		"eor r3, r3, r9, ror #20;"
  		"eor r3, r3, r9, ror #14;"
  		"eor r3, r3, r9, ror #8;"
  		"eor r3, r3, r9, ror #3;"

  		"eor r4, r4, r10, ror #27;"			//mix columns for the r4 register is calculated
  		"eor r4, r4, r10, ror #23;"
  		"eor r4, r4, r10, ror #19;"
  		"eor r4, r4, r10, ror #13;"
  		"eor r4, r4, r10, ror #7;"
  		"eor r4, r4, r10, ror #2;"

  		"eor r5, r5, r11, ror #26;"			//mix columns for the r5 register is calculated
  		"eor r5, r5, r11, ror #22;"
  		"eor r5, r5, r11, ror #18;"
  		"eor r5, r5, r11, ror #12;"
  		"eor r5, r5, r11, ror #6;"
  		"eor r5, r5, r11, ror #1;"
  		/* mix columns end*/
  	);

  	asm(	/*		Round constants in bitslice representation		*/
  		/*		register from r6 to r12 haven't valid data erase them	*/
  		"mov 	r6, 0X501C;"				//move the round constant low part in bitslice representation	bit 0
  		"movt	r6, 0X3903;"				//move the round constant high part in bitslice representation  bit 0
  		"mov	r7, 0X5A05;"				//move the round constant low part in bitslice representation   bit 1
  		"movt	r7, 0X2214;"				//move the round constant high part in bitslice representation  bit 1
  		"mov	r8, 0X05B0;"				//move the round constant low part in bitslice representation	bit 2
  		"movt	r8, 0XB467;"				//move the round constant high part in bitslice representation  bit 2
  		"mov	r9, 0X408A;"				//move the round constant low part in bitslice representation	bit 3
  		"movt	r9, 0X2269;"				//move the round constant high part in bitslice representation  bit 3
  		"mov	r10, 0X54CE;"				//move the round constant low part in bitslice representation	bit 4
  		"movt	r10, 0X5B99;"				//move the round constant high part in bitslice representation  bit 4
  		"mov	r11, 0X791E;"				//move the round constant low part in bitslice representation	bit 5
  		"movt   r11, 0XE150;"				//move the round constant high part in bitslice representation  bit 5
  		/*		add round constant to the state i.e. blk i xor constant i		*/
  		"eor r0, r0, r6;"
  		"eor r1, r1, r7;"
  		"eor r2, r2, r8;"
  		"eor r3, r3, r9;"
  		"eor r4, r4, r10;"
  		"eor r5, r5, r11;"
  		/*at this point the 0 round is done the results are in r0 - r5 then r6 - r12 can be clean*/
  	);

  ///////////// round  1 //////////////
  	asm(/*	ARK	 the key 1 must be in bitslice*/
  		"ldr r6, [sp, #24];"				//load bitslice key [1]  only bit "b_0"
  		"ldr r7, [sp, #28];"				//load bitslice key [1]  only bit "b_1"
  		"ldr r8, [sp, #32];"				//load bitslice key [1]  only bit "b_2"
  		"ldr r9, [sp, #36];"				//load bitslice key [1]  only bit "b_3"
  		"ldr r10, [sp, #40];"				//load bitslice key [1]  only bit "b_4"
  		"ldr r11, [sp, #44];"				//load bitslice key [1]  only bit "b_5"
  		/* XOR each register with the key position bit*/
  		"eor r0, r0, r6;"
  		"eor r1, r1, r7;"
  		"eor r2, r2, r8;"
  		"eor r3, r3, r9;"
  		"eor r4, r4, r10;"
  		"eor r5, r5, r11;"
  		/*EN of ARK*/
  	);

  	asm(	/*		Sbox implementation in assembly		*/
  		"and r9, r4, r2;"					//  r9  <= r2 and r4
  		"orn r9, r9, r5;"					//  r9  <= not((r2 and r4) or r5)
  		"and r9, r9, r3;"					//	r9  <= r3 and not((r2 and r4) or r5)
  		"and r10, r5, r4;"					//	r10 <= (r5 and r4)
  		"orn r11, r3, r0;"					//	r11 <= not(r3 or r0)
  		"orn r10, r10, r11;"				//	r10 <= not((r5 and r4) or (not(r3 or r0)))
  		"and r10, r1, r10;"					//	r10 <= (not((r5 and r4) or (not(r3 or r0)))) and (r1)
  		"orr r6, r10, r9;"					//	r6  <= (((not((r5 and r4) or (not(r3 or r0)))) and (r1)) or (r3 and not((r2 and r4) or r5)))

  		"and r9, r0, r2;"					//	r9  <= (r0 and r2)			r9 	overwrite
  		"orn r10, r2, r3;"					//	r10 <= not(r2 or r3)		r10 overwrite
  		"orn r9, r9, r10;"					//	r9	<= not((r0 and r0) or (not(r2 or r3)))
  		"and r9, r9, r5;"					//	r9	<= ((not((r0 and r0) or (not(r2 or r3)))) and r5)
  		"orr r10, r5, r4;"					//	r10 <= (r5 or r4)			r10 overwrite
  		"orn r10, r10, r3;"					//	r10 <= not((not(r5 or r4)) or r3)
  		"orn r9, r9, r10;"					//	r9 	<= not(((not((r0 and r0) or (not(r2 or r3)))) and r5) or (not((not(r5 or r4)) or r3)))
  		"orr r10, r0, r3;"					//	r10 <= (r0 or r3)			r10	overwrite
  		"orn r10, r10, r1;"					//	r10	<= not((r0 or r3) or r1)
  		"orn r7, r9, r10;"					//	r7	<= not((not(((not((r0 and r0) or (not(r2 or r3)))) and r5) or (not((not(r5 or r4)) or r3)))) or (not((r0 or r3) or r1)) )

  		"and r9, r1, r3;"					//	r9 	<= (r1 and r3)			r9	overwrite
  		"orn r10, r3, r4;"					//	r10 <= not(r3 or r4)		r10	overwrite
  		"orn r9, r9, r10;"					//	r9	<= not((not(r3 or r4)) or (r1 and r3))
  		"and r9, r0, r9;"					//	r9	<= ((not((not(r3 or r4)) or (r1 and r3))) and r0)
  		"orr r10, r3, r4;"					//	r10 <= (r3 or r4)			r10	overwrite
  		"orn r10, r10, r2;"					//	r10	<= not((r3 or r4) or r2)
  		"orn r9, r9, r10;"					//	r9	<= not(((not((not(r3 or r4)) or (r1 and r3))) and r0) or (not((r3 or r4) or r2)) )
  		"orr r10, r0, r2;"					//	r10	<= (r0 or r2)			r10	overwrite
  		"orr r10, r10, r5;"					//	r10 <= ((r0 or r2) or r5)
  		"orn r8, r9, r10;"					//	r8	<= not((not(((not((not(r3 or r4)) or (r1 and r3))) and r0) or (not((r3 or r4) or r2)))) or (((r0 or r2) or r5)))

  		"and r9, r0, r4;"					//	r9	<= (r0 and r4)			r9	overwrite
  		"orr r10, r0, r3;"					//	r10	<= (r0 or r3)			r10 overwrite
  		"orn r9, r9, r10;"					//	r9	<= not((r0 and r4) or (r0 or r3))
  		"and r9, r9, r2;"					//	r9	<= ((not((r0 and r4) or (r0 or r3))) and r2)
  		"and r10, r0, r5;"					//	r10 <= (r0 and r5)			r10	overwrite
  		"orn r10, r2, r10;"					//	r10	<= not((r0 and r5) or r2)
  		"orn r9, r9, r10;"					//	r9	<= not(((not((r0 and r4) or (r0 or r3))) and r2) or (not((r0 and r5) or r2)))
  		"and r10, r1, r3;"					//	r10 <= (r1 and r3)			r10 overwrite
  		"orn r10, r0, r10;"					//	r10	<= not((r1 and r3) or r0)
  		"orn r9, r9, r10;"					//	r9	<= not((not(((not((r0 and r4) or (r0 or r3))) and r2) or (not((r0 and r5) or r2)))) or (not((r1 and r3) or r0)))

  		"eor r12, r12, r12;"  		     	//	r12 <= 0's

  		"orr r10, r4, r2;"					//	r10	<= (r4 or r2)
  		"orr r11, r0, r1;"					//	r11 <= (r0 or r1)
  		"orn r10, r10, r11;"				//	r10	<= not((r4 or r2) or (r0 or r1))
  		"orn r10, r12, r10;"				//	r10	<= not(() or (not((r4 or r2) or (r0 or r1))))
  		"orn r11, r3, r0;"					//	r11	<= not( r3 or r0)		r11	overwrite
  		"orn r10, r10, r11;"				//	r10	<= not((not(() or (not((r4 or r2) or (r0 or r1))))) or (not( r3 or r0)))
  		"and r11, r4, r5;"					//	r11	<= (r4 and r5)			r11	overwrite
  		"orn r11, r0, r11;"					//	r11 <= not((r4 and r5) or r0)
  		"orn r10, r10, r11;"				//	r10 <= not((not((not(() or (not((r4 or r2) or (r0 or r1))))) or (not( r3 or r0)))) or (not((r4 and r5) or r0)))

  		"and r12, r0, r3;"					//  r12 <= (r0 and r3)			r12	overwrite
  		"orn r11, r2, r4;"					//	r11	<= not(r2 or r4)		r11	overwrite
  		"orn r12, r12, r11;"				//	r12	<= not(((r0 and r3)) or (not(r2 or r4)))
  		"orn r12, r1, r12;"					//	r12	<= not((not(((r0 and r3)) or (not(r2 or r4)))) or r1)
  		"and r11, r1, r0;"					//	r11	<= (r1 and r0)
  		"orr r11, r11, r5;"					//	r11	<= ((r1 and r0) or r5)
  		"and r11, r11, r2;"					//	r11	<= (((r1 and r0) or r5) and r2)
  		"orn r11, r11, r12;"				//	r11	<= not((((r1 and r0) or r5) and r2) or (not((not(((r0 and r3)) or (not(r2 or r4)))) or r1)))
  		/*		Sbox implementation assembly end	*/
  	);

  	asm(	/* shift columns */
  		"mov r0, r6;"
  		"mov r1, r7, ror #31;"
  		"mov r2, r8, ror #30;"
  		"mov r3, r9, ror #29;"
  		"mov r4, r10, ror #28;"
  		"mov r5, r11, ror #27;"
  		/* shift columns end */
  	);

  	asm(/*		Sbox implementation in assembly		*/
  		"and r9, r4, r2;"					//  r9  <= r2 and r4
  		"orn r9, r9, r5;"					//  r9  <= not((r2 and r4) or r5)
  		"and r9, r9, r3;"					//	r9  <= r3 and not((r2 and r4) or r5)
  		"and r10, r5, r4;"					//	r10 <= (r5 and r4)
  		"orn r11, r3, r0;"					//	r11 <= not(r3 or r0)
  		"orn r10, r10, r11;"				//	r10 <= not((r5 and r4) or (not(r3 or r0)))
  		"and r10, r1, r10;"					//	r10 <= (not((r5 and r4) or (not(r3 or r0)))) and (r1)
  		"orr r6, r10, r9;"					//	r6  <= (((not((r5 and r4) or (not(r3 or r0)))) and (r1)) or (r3 and not((r2 and r4) or r5)))

  		"and r9, r0, r2;"					//	r9  <= (r0 and r2)			r9 	overwrite
  		"orn r10, r2, r3;"					//	r10 <= not(r2 or r3)		r10 overwrite
  		"orn r9, r9, r10;"					//	r9	<= not((r0 and r0) or (not(r2 or r3)))
  		"and r9, r9, r5;"					//	r9	<= ((not((r0 and r0) or (not(r2 or r3)))) and r5)
  		"orr r10, r5, r4;"					//	r10 <= (r5 or r4)			r10 overwrite
  		"orn r10, r10, r3;"					//	r10 <= not((not(r5 or r4)) or r3)
  		"orn r9, r9, r10;"					//	r9 	<= not(((not((r0 and r0) or (not(r2 or r3)))) and r5) or (not((not(r5 or r4)) or r3)))
  		"orr r10, r0, r3;"					//	r10 <= (r0 or r3)			r10	overwrite
  		"orn r10, r10, r1;"					//	r10	<= not((r0 or r3) or r1)
  		"orn r7, r9, r10;"					//	r7	<= not((not(((not((r0 and r0) or (not(r2 or r3)))) and r5) or (not((not(r5 or r4)) or r3)))) or (not((r0 or r3) or r1)) )

  		"and r9, r1, r3;"					//	r9 	<= (r1 and r3)			r9	overwrite
  		"orn r10, r3, r4;"					//	r10 <= not(r3 or r4)		r10	overwrite
  		"orn r9, r9, r10;"					//	r9	<= not((not(r3 or r4)) or (r1 and r3))
  		"and r9, r0, r9;"					//	r9	<= ((not((not(r3 or r4)) or (r1 and r3))) and r0)
  		"orr r10, r3, r4;"					//	r10 <= (r3 or r4)			r10	overwrite
  		"orn r10, r10, r2;"					//	r10	<= not((r3 or r4) or r2)
  		"orn r9, r9, r10;"					//	r9	<= not(((not((not(r3 or r4)) or (r1 and r3))) and r0) or (not((r3 or r4) or r2)) )
  		"orr r10, r0, r2;"					//	r10	<= (r0 or r2)			r10	overwrite
  		"orr r10, r10, r5;"					//	r10 <= ((r0 or r2) or r5)
  		"orn r8, r9, r10;"					//	r8	<= not((not(((not((not(r3 or r4)) or (r1 and r3))) and r0) or (not((r3 or r4) or r2)))) or (((r0 or r2) or r5)))

  		"and r9, r0, r4;"					//	r9	<= (r0 and r4)			r9	overwrite
  		"orr r10, r0, r3;"					//	r10	<= (r0 or r3)			r10 overwrite
  		"orn r9, r9, r10;"					//	r9	<= not((r0 and r4) or (r0 or r3))
  		"and r9, r9, r2;"					//	r9	<= ((not((r0 and r4) or (r0 or r3))) and r2)
  		"and r10, r0, r5;"					//	r10 <= (r0 and r5)			r10	overwrite
  		"orn r10, r2, r10;"					//	r10	<= not((r0 and r5) or r2)
  		"orn r9, r9, r10;"					//	r9	<= not(((not((r0 and r4) or (r0 or r3))) and r2) or (not((r0 and r5) or r2)))
  		"and r10, r1, r3;"					//	r10 <= (r1 and r3)			r10 overwrite
  		"orn r10, r0, r10;"					//	r10	<= not((r1 and r3) or r0)
  		"orn r9, r9, r10;"					//	r9	<= not((not(((not((r0 and r4) or (r0 or r3))) and r2) or (not((r0 and r5) or r2)))) or (not((r1 and r3) or r0)))

  		"eor r12, r12, r12;"   			  	//	r12 <= 0's

  		"orr r10, r4, r2;"					//	r10	<= (r4 or r2)
  		"orr r11, r0, r1;"					//	r11 <= (r0 or r1)
  		"orn r10, r10, r11;"				//	r10	<= not((r4 or r2) or (r0 or r1))
  		"orn r10, r12, r10;"				//	r10	<= not(() or (not((r4 or r2) or (r0 or r1))))
  		"orn r11, r3, r0;"					//	r11	<= not( r3 or r0)		r11	overwrite
  		"orn r10, r10, r11;"				//	r10	<= not((not(() or (not((r4 or r2) or (r0 or r1))))) or (not( r3 or r0)))
  		"and r11, r4, r5;"					//	r11	<= (r4 and r5)			r11	overwrite
  		"orn r11, r0, r11;"					//	r11 <= not((r4 and r5) or r0)
  		"orn r10, r10, r11;"				//	r10 <= not((not((not(() or (not((r4 or r2) or (r0 or r1))))) or (not( r3 or r0)))) or (not((r4 and r5) or r0)))

  		"and r12, r0, r3;"					//  r12 <= (r0 and r3)			r12	overwrite
  		"orn r11, r2, r4;"					//	r11	<= not(r2 or r4)		r11	overwrite
  		"orn r12, r12, r11;"				//	r12	<= not(((r0 and r3)) or (not(r2 or r4)))
  		"orn r12, r1, r12;"					//	r12	<= not((not(((r0 and r3)) or (not(r2 or r4)))) or r1)
  		"and r11, r1, r0;"					//	r11	<= (r1 and r0)
  		"orr r11, r11, r5;"					//	r11	<= ((r1 and r0) or r5)
  		"and r11, r11, r2;"					//	r11	<= (((r1 and r0) or r5) and r2)
  		"orn r11, r11, r12;"				//	r11	<= not((((r1 and r0) or r5) and r2) or (not((not(((r0 and r3)) or (not(r2 or r4)))) or r1)))
  		/*		Sbox implementation assembly end	*/
  	);

  	asm(	/* shift columns */
  		"mov r0, r6;"
  		"mov r1, r7, ror #31;"
  		"mov r2, r8, ror #30;"
  		"mov r3, r9, ror #29;"
  		"mov r4, r10, ror #28;"
  		"mov r5, r11, ror #27;"
  		/* shift columns end */
  	);

  	asm(	/* mix columns*/
  		"eor r0, r0, r6, ror #31;" 			//here the mix columns for the r0 register is calculated
  		"eor r0, r0, r6, ror #27;"
  		"eor r0, r0, r6, ror #23;"
  		"eor r0, r0, r6, ror #17;"
  		"eor r0, r0, r6, ror #11;"
  		"eor r0, r0, r6, ror #6;"

  		"eor r1, r1, r7, ror #30;"			//mix columns for the r1 register is calculated
  		"eor r1, r1, r7, ror #26;"
  		"eor r1, r1, r7, ror #22;"
  		"eor r1, r1, r7, ror #16;"
  		"eor r1, r1, r7, ror #10;"
  		"eor r1, r1, r7, ror #5;"

  		"eor r2, r2, r8, ror #29;"			//mix columns for the r2 register is calculated
  		"eor r2, r2, r8, ror #25;"
  		"eor r2, r2, r8, ror #21;"
  		"eor r2, r2, r8, ror #15;"
  		"eor r2, r2, r8, ror #9;"
  		"eor r2, r2, r8, ror #4;"

  		"eor r3, r3, r9, ror #28;"			//mix columns for the r3 register is calculated
  		"eor r3, r3, r9, ror #24;"
  		"eor r3, r3, r9, ror #20;"
  		"eor r3, r3, r9, ror #14;"
  		"eor r3, r3, r9, ror #8;"
  		"eor r3, r3, r9, ror #3;"

  		"eor r4, r4, r10, ror #27;"			//mix columns for the r4 register is calculated
  		"eor r4, r4, r10, ror #23;"
  		"eor r4, r4, r10, ror #19;"
  		"eor r4, r4, r10, ror #13;"
  		"eor r4, r4, r10, ror #7;"
  		"eor r4, r4, r10, ror #2;"

  		"eor r5, r5, r11, ror #26;"			//mix columns for the r5 register is calculated
  		"eor r5, r5, r11, ror #22;"
  		"eor r5, r5, r11, ror #18;"
  		"eor r5, r5, r11, ror #12;"
  		"eor r5, r5, r11, ror #6;"
  		"eor r5, r5, r11, ror #1;"
  		/* mix columns end*/
  	);

  	asm(	/*		Round constants in bitslice representation		*/
  		/*		register from r6 to r12 haven't valid data erase them	*/
  		"mov 	r6, 0X067B;"				//move the round constant low part in bitslice representation	bit 0
  		"movt	r6, 0X3A21;"				//move the round constant high part in bitslice representation  bit 0
  		"mov	r7, 0X1FBE;"				//move the round constant low part in bitslice representation   bit 1
  		"movt	r7, 0X3280;"				//move the round constant high part in bitslice representation  bit 1
  		"mov	r8, 0XCEE9;"				//move the round constant low part in bitslice representation	bit 2
  		"movt	r8, 0X35C8;"				//move the round constant high part in bitslice representation  bit 2
  		"mov	r9, 0XC971;"				//move the round constant low part in bitslice representation	bit 3
  		"movt	r9, 0X0D33;"				//move the round constant high part in bitslice representation  bit 3
  		"mov	r10, 0X9408;"				//move the round constant low part in bitslice representation	bit 4
  		"movt	r10, 0XFD8F;"				//move the round constant high part in bitslice representation  bit 4
  		"mov	r11, 0X5E82;"				//move the round constant low part in bitslice representation	bit 5
  		"movt   r11, 0X22B2;"				//move the round constant high part in bitslice representation  bit 5
  	/*		add round constant to the state i.e. blk i xor constant i		*/
  		"eor r0, r0, r6;"
  		"eor r1, r1, r7;"
  		"eor r2, r2, r8;"
  		"eor r3, r3, r9;"
  		"eor r4, r4, r10;"
  		"eor r5, r5, r11;"
  );
  	/*at this point the 1st round is done the results are in r0 - r5 then r6 - r12 can be clean*/

  ///////////// round  2 //////////////
  	asm(	/*	ARK	 the key must be in bitslice*/
  		"ldr r6, [sp, #48];"				//load bitslice key [2]  only bit "b_0"
  		"ldr r7, [sp, #52];"				//load bitslice key [2]  only bit "b_1"
  		"ldr r8, [sp, #56];"				//load bitslice key [2]  only bit "b_2"
  		"ldr r9, [sp, #60];"				//load bitslice key [2]  only bit "b_3"
  		"ldr r10, [sp, #64];"				//load bitslice key [2]  only bit "b_4"
  		"ldr r11, [sp, #68];"				//load bitslice key [2]  only bit "b_5"
  		/* XOR each register with the key position bit*/
  		"eor r0, r0, r6;"
  		"eor r1, r1, r7;"
  		"eor r2, r2, r8;"
  		"eor r3, r3, r9;"
  		"eor r4, r4, r10;"
  		"eor r5, r5, r11;"
  		/*EN of ARK*/
  	);

  	asm(/*		Sbox implementation in assembly		*/
  		"and r9, r4, r2;"					//  r9  <= r2 and r4
  		"orn r9, r9, r5;"					//  r9  <= not((r2 and r4) or r5)
  		"and r9, r9, r3;"					//	r9  <= r3 and not((r2 and r4) or r5)
  		"and r10, r5, r4;"					//	r10 <= (r5 and r4)
  		"orn r11, r3, r0;"					//	r11 <= not(r3 or r0)
  		"orn r10, r10, r11;"				//	r10 <= not((r5 and r4) or (not(r3 or r0)))
  		"and r10, r1, r10;"					//	r10 <= (not((r5 and r4) or (not(r3 or r0)))) and (r1)
  		"orr r6, r10, r9;"					//	r6  <= (((not((r5 and r4) or (not(r3 or r0)))) and (r1)) or (r3 and not((r2 and r4) or r5)))

  		"and r9, r0, r2;"					//	r9  <= (r0 and r2)			r9 	overwrite
  		"orn r10, r2, r3;"					//	r10 <= not(r2 or r3)		r10 overwrite
  		"orn r9, r9, r10;"					//	r9	<= not((r0 and r0) or (not(r2 or r3)))
  		"and r9, r9, r5;"					//	r9	<= ((not((r0 and r0) or (not(r2 or r3)))) and r5)
  		"orr r10, r5, r4;"					//	r10 <= (r5 or r4)			r10 overwrite
  		"orn r10, r10, r3;"					//	r10 <= not((not(r5 or r4)) or r3)
  		"orn r9, r9, r10;"					//	r9 	<= not(((not((r0 and r0) or (not(r2 or r3)))) and r5) or (not((not(r5 or r4)) or r3)))
  		"orr r10, r0, r3;"					//	r10 <= (r0 or r3)			r10	overwrite
  		"orn r10, r10, r1;"					//	r10	<= not((r0 or r3) or r1)
  		"orn r7, r9, r10;"					//	r7	<= not((not(((not((r0 and r0) or (not(r2 or r3)))) and r5) or (not((not(r5 or r4)) or r3)))) or (not((r0 or r3) or r1)) )

  		"and r9, r1, r3;"					//	r9 	<= (r1 and r3)			r9	overwrite
  		"orn r10, r3, r4;"					//	r10 <= not(r3 or r4)		r10	overwrite
  		"orn r9, r9, r10;"					//	r9	<= not((not(r3 or r4)) or (r1 and r3))
  		"and r9, r0, r9;"					//	r9	<= ((not((not(r3 or r4)) or (r1 and r3))) and r0)
  		"orr r10, r3, r4;"					//	r10 <= (r3 or r4)			r10	overwrite
  		"orn r10, r10, r2;"					//	r10	<= not((r3 or r4) or r2)
  		"orn r9, r9, r10;"					//	r9	<= not(((not((not(r3 or r4)) or (r1 and r3))) and r0) or (not((r3 or r4) or r2)) )
  		"orr r10, r0, r2;"					//	r10	<= (r0 or r2)			r10	overwrite
  		"orr r10, r10, r5;"					//	r10 <= ((r0 or r2) or r5)
  		"orn r8, r9, r10;"					//	r8	<= not((not(((not((not(r3 or r4)) or (r1 and r3))) and r0) or (not((r3 or r4) or r2)))) or (((r0 or r2) or r5)))

  		"and r9, r0, r4;"					//	r9	<= (r0 and r4)			r9	overwrite
  		"orr r10, r0, r3;"					//	r10	<= (r0 or r3)			r10 overwrite
  		"orn r9, r9, r10;"					//	r9	<= not((r0 and r4) or (r0 or r3))
  		"and r9, r9, r2;"					//	r9	<= ((not((r0 and r4) or (r0 or r3))) and r2)
  		"and r10, r0, r5;"					//	r10 <= (r0 and r5)			r10	overwrite
  		"orn r10, r2, r10;"					//	r10	<= not((r0 and r5) or r2)
  		"orn r9, r9, r10;"					//	r9	<= not(((not((r0 and r4) or (r0 or r3))) and r2) or (not((r0 and r5) or r2)))
  		"and r10, r1, r3;"					//	r10 <= (r1 and r3)			r10 overwrite
  		"orn r10, r0, r10;"					//	r10	<= not((r1 and r3) or r0)
  		"orn r9, r9, r10;"					//	r9	<= not((not(((not((r0 and r4) or (r0 or r3))) and r2) or (not((r0 and r5) or r2)))) or (not((r1 and r3) or r0)))

  		"eor r12, r12, r12;"  		     	//	r12 <= 0's

  		"orr r10, r4, r2;"					//	r10	<= (r4 or r2)
  		"orr r11, r0, r1;"					//	r11 <= (r0 or r1)
  		"orn r10, r10, r11;"				//	r10	<= not((r4 or r2) or (r0 or r1))
  		"orn r10, r12, r10;"				//	r10	<= not(() or (not((r4 or r2) or (r0 or r1))))
  		"orn r11, r3, r0;"					//	r11	<= not( r3 or r0)		r11	overwrite
  		"orn r10, r10, r11;"				//	r10	<= not((not(() or (not((r4 or r2) or (r0 or r1))))) or (not( r3 or r0)))
  		"and r11, r4, r5;"					//	r11	<= (r4 and r5)			r11	overwrite
  		"orn r11, r0, r11;"					//	r11 <= not((r4 and r5) or r0)
  		"orn r10, r10, r11;"				//	r10 <= not((not((not(() or (not((r4 or r2) or (r0 or r1))))) or (not( r3 or r0)))) or (not((r4 and r5) or r0)))

  		"and r12, r0, r3;"					//  r12 <= (r0 and r3)			r12	overwrite
  		"orn r11, r2, r4;"					//	r11	<= not(r2 or r4)		r11	overwrite
  		"orn r12, r12, r11;"				//	r12	<= not(((r0 and r3)) or (not(r2 or r4)))
  		"orn r12, r1, r12;"					//	r12	<= not((not(((r0 and r3)) or (not(r2 or r4)))) or r1)
  		"and r11, r1, r0;"					//	r11	<= (r1 and r0)
  		"orr r11, r11, r5;"					//	r11	<= ((r1 and r0) or r5)
  		"and r11, r11, r2;"					//	r11	<= (((r1 and r0) or r5) and r2)
  		"orn r11, r11, r12;"				//	r11	<= not((((r1 and r0) or r5) and r2) or (not((not(((r0 and r3)) or (not(r2 or r4)))) or r1)))
  		/*		Sbox implementation assembly end	*/
  	);

  	asm(	/* shift columns */
  		"mov r0, r6;"
  		"mov r1, r7, ror #31;"
  		"mov r2, r8, ror #30;"
  		"mov r3, r9, ror #29;"
  		"mov r4, r10, ror #28;"
  		"mov r5, r11, ror #27;"
  		/* shift columns end */
  	);

  	asm(/*		Sbox implementation in assembly		*/
  		"and r9, r4, r2;"					//  r9  <= r2 and r4
  		"orn r9, r9, r5;"					//  r9  <= not((r2 and r4) or r5)
  		"and r9, r9, r3;"					//	r9  <= r3 and not((r2 and r4) or r5)
  		"and r10, r5, r4;"					//	r10 <= (r5 and r4)
  		"orn r11, r3, r0;"					//	r11 <= not(r3 or r0)
  		"orn r10, r10, r11;"				//	r10 <= not((r5 and r4) or (not(r3 or r0)))
  		"and r10, r1, r10;"					//	r10 <= (not((r5 and r4) or (not(r3 or r0)))) and (r1)
  		"orr r6, r10, r9;"					//	r6  <= (((not((r5 and r4) or (not(r3 or r0)))) and (r1)) or (r3 and not((r2 and r4) or r5)))

  		"and r9, r0, r2;"					//	r9  <= (r0 and r2)			r9 	overwrite
  		"orn r10, r2, r3;"					//	r10 <= not(r2 or r3)		r10 overwrite
  		"orn r9, r9, r10;"					//	r9	<= not((r0 and r0) or (not(r2 or r3)))
  		"and r9, r9, r5;"					//	r9	<= ((not((r0 and r0) or (not(r2 or r3)))) and r5)
  		"orr r10, r5, r4;"					//	r10 <= (r5 or r4)			r10 overwrite
  		"orn r10, r10, r3;"					//	r10 <= not((not(r5 or r4)) or r3)
  		"orn r9, r9, r10;"					//	r9 	<= not(((not((r0 and r0) or (not(r2 or r3)))) and r5) or (not((not(r5 or r4)) or r3)))
  		"orr r10, r0, r3;"					//	r10 <= (r0 or r3)			r10	overwrite
  		"orn r10, r10, r1;"					//	r10	<= not((r0 or r3) or r1)
  		"orn r7, r9, r10;"					//	r7	<= not((not(((not((r0 and r0) or (not(r2 or r3)))) and r5) or (not((not(r5 or r4)) or r3)))) or (not((r0 or r3) or r1)) )

  		"and r9, r1, r3;"					//	r9 	<= (r1 and r3)			r9	overwrite
  		"orn r10, r3, r4;"					//	r10 <= not(r3 or r4)		r10	overwrite
  		"orn r9, r9, r10;"					//	r9	<= not((not(r3 or r4)) or (r1 and r3))
  		"and r9, r0, r9;"					//	r9	<= ((not((not(r3 or r4)) or (r1 and r3))) and r0)
  		"orr r10, r3, r4;"					//	r10 <= (r3 or r4)			r10	overwrite
  		"orn r10, r10, r2;"					//	r10	<= not((r3 or r4) or r2)
  		"orn r9, r9, r10;"					//	r9	<= not(((not((not(r3 or r4)) or (r1 and r3))) and r0) or (not((r3 or r4) or r2)) )
  		"orr r10, r0, r2;"					//	r10	<= (r0 or r2)			r10	overwrite
  		"orr r10, r10, r5;"					//	r10 <= ((r0 or r2) or r5)
  		"orn r8, r9, r10;"					//	r8	<= not((not(((not((not(r3 or r4)) or (r1 and r3))) and r0) or (not((r3 or r4) or r2)))) or (((r0 or r2) or r5)))

  		"and r9, r0, r4;"					//	r9	<= (r0 and r4)			r9	overwrite
  		"orr r10, r0, r3;"					//	r10	<= (r0 or r3)			r10 overwrite
  		"orn r9, r9, r10;"					//	r9	<= not((r0 and r4) or (r0 or r3))
  		"and r9, r9, r2;"					//	r9	<= ((not((r0 and r4) or (r0 or r3))) and r2)
  		"and r10, r0, r5;"					//	r10 <= (r0 and r5)			r10	overwrite
  		"orn r10, r2, r10;"					//	r10	<= not((r0 and r5) or r2)
  		"orn r9, r9, r10;"					//	r9	<= not(((not((r0 and r4) or (r0 or r3))) and r2) or (not((r0 and r5) or r2)))
  		"and r10, r1, r3;"					//	r10 <= (r1 and r3)			r10 overwrite
  		"orn r10, r0, r10;"					//	r10	<= not((r1 and r3) or r0)
  		"orn r9, r9, r10;"					//	r9	<= not((not(((not((r0 and r4) or (r0 or r3))) and r2) or (not((r0 and r5) or r2)))) or (not((r1 and r3) or r0)))

  		"eor r12, r12, r12;"   			  	// r12 <= 0's

  		"orr r10, r4, r2;"					//	r10	<= (r4 or r2)
  		"orr r11, r0, r1;"					//	r11 <= (r0 or r1)
  		"orn r10, r10, r11;"				//	r10	<= not((r4 or r2) or (r0 or r1))
  		"orn r10, r12, r10;"				//	r10	<= not(() or (not((r4 or r2) or (r0 or r1))))
  		"orn r11, r3, r0;"					//	r11	<= not( r3 or r0)		r11	overwrite
  		"orn r10, r10, r11;"				//	r10	<= not((not(() or (not((r4 or r2) or (r0 or r1))))) or (not( r3 or r0)))
  		"and r11, r4, r5;"					//	r11	<= (r4 and r5)			r11	overwrite
  		"orn r11, r0, r11;"					//	r11 <= not((r4 and r5) or r0)
  		"orn r10, r10, r11;"				//	r10 <= not((not((not(() or (not((r4 or r2) or (r0 or r1))))) or (not( r3 or r0)))) or (not((r4 and r5) or r0)))

  		"and r12, r0, r3;"					//  r12 <= (r0 and r3)			r12	overwrite
  		"orn r11, r2, r4;"					//	r11	<= not(r2 or r4)		r11	overwrite
  		"orn r12, r12, r11;"				//	r12	<= not(((r0 and r3)) or (not(r2 or r4)))
  		"orn r12, r1, r12;"					//	r12	<= not((not(((r0 and r3)) or (not(r2 or r4)))) or r1)
  		"and r11, r1, r0;"					//	r11	<= (r1 and r0)
  		"orr r11, r11, r5;"					//	r11	<= ((r1 and r0) or r5)
  		"and r11, r11, r2;"					//	r11	<= (((r1 and r0) or r5) and r2)
  		"orn r11, r11, r12;"				//	r11	<= not((((r1 and r0) or r5) and r2) or (not((not(((r0 and r3)) or (not(r2 or r4)))) or r1)))
  		/*		Sbox implementation assembly end	*/
  	);

  	asm(	/* shift columns */
  		"mov r0, r6;"
  		"mov r1, r7, ror #31;"
  		"mov r2, r8, ror #30;"
  		"mov r3, r9, ror #29;"
  		"mov r4, r10, ror #28;"
  		"mov r5, r11, ror #27;"
  		/* shift columns end */
  	);

  	asm(	/* mix columns*/
  		"eor r0, r0, r6, ror #31;" 			//here the mix columns for the r0 register is calculated
  		"eor r0, r0, r6, ror #27;"
  		"eor r0, r0, r6, ror #23;"
  		"eor r0, r0, r6, ror #17;"
  		"eor r0, r0, r6, ror #11;"
  		"eor r0, r0, r6, ror #6;"

  		"eor r1, r1, r7, ror #30;"			//mix columns for the r1 register is calculated
  		"eor r1, r1, r7, ror #26;"
  		"eor r1, r1, r7, ror #22;"
  		"eor r1, r1, r7, ror #16;"
  		"eor r1, r1, r7, ror #10;"
  		"eor r1, r1, r7, ror #5;"

  		"eor r2, r2, r8, ror #29;"			//mix columns for the r2 register is calculated
  		"eor r2, r2, r8, ror #25;"
  		"eor r2, r2, r8, ror #21;"
  		"eor r2, r2, r8, ror #15;"
  		"eor r2, r2, r8, ror #9;"
  		"eor r2, r2, r8, ror #4;"

  		"eor r3, r3, r9, ror #28;"			//mix columns for the r3 register is calculated
  		"eor r3, r3, r9, ror #24;"
  		"eor r3, r3, r9, ror #20;"
  		"eor r3, r3, r9, ror #14;"
  		"eor r3, r3, r9, ror #8;"
  		"eor r3, r3, r9, ror #3;"

  		"eor r4, r4, r10, ror #27;"			//mix columns for the r4 register is calculated
  		"eor r4, r4, r10, ror #23;"
  		"eor r4, r4, r10, ror #19;"
  		"eor r4, r4, r10, ror #13;"
  		"eor r4, r4, r10, ror #7;"
  		"eor r4, r4, r10, ror #2;"

  		"eor r5, r5, r11, ror #26;"			//mix columns for the r5 register is calculated
  		"eor r5, r5, r11, ror #22;"
  		"eor r5, r5, r11, ror #18;"
  		"eor r5, r5, r11, ror #12;"
  		"eor r5, r5, r11, ror #6;"
  		"eor r5, r5, r11, ror #1;"
  		/* mix columns end*/
  	);

  	asm(	/*		Round constants in bitslice representation		*/
  		/*		register from r6 to r12 haven't valid data erase them	*/
  		"mov 	r6, 0X84A2;"				//move the round constant low part in bitslice representation	bit 0
  		"movt	r6, 0XBF39;"				//move the round constant high part in bitslice representation  bit 0
  		"mov	r7, 0X65CD;"				//move the round constant low part in bitslice representation   bit 1
  		"movt	r7, 0XA5B3;"				//move the round constant high part in bitslice representation  bit 1
  		"mov	r8, 0XB65F;"				//move the round constant low part in bitslice representation	bit 2
  		"movt	r8, 0X5D54;"				//move the round constant high part in bitslice representation  bit 2
  		"mov	r9, 0XE9EE;"				//move the round constant low part in bitslice representation	bit 3
  		"movt	r9, 0X0FF7;"				//move the round constant high part in bitslice representation  bit 3
  		"mov	r10, 0X012D;"				//move the round constant low part in bitslice representation	bit 4
  		"movt	r10, 0X4012;"				//move the round constant high part in bitslice representation  bit 4
  		"mov	r11, 0X9CD5;"				//move the round constant low part in bitslice representation	bit 5
  		"movt   r11, 0X1A5D;"				//move the round constant high part in bitslice representation  bit 5
  /*		add round constant to the state i.e. blk i xor constant i		*/
  		"eor r0, r0, r6;"
  		"eor r1, r1, r7;"
  		"eor r2, r2, r8;"
  		"eor r3, r3, r9;"
  		"eor r4, r4, r10;"
  		"eor r5, r5, r11;"
  		"eor r12, r12;"
  );
  	/*at this point the 2nd round is done the results are in r0 - r5 then r6 - r12 can be clean*/

  ///////////// round  3 //////////////
  	asm(/*	ARK	 the key must be in bitslice*/
  		"ldr r6, [sp, #72];"				//load bitslice key [3]  only bit "b_0"
  		"ldr r7, [sp, #76];"				//load bitslice key [3]  only bit "b_1"
  		"ldr r8, [sp, #80];"				//load bitslice key [3]  only bit "b_2"
  		"ldr r9, [sp, #84];"				//load bitslice key [3]  only bit "b_3"
  		"ldr r10, [sp, #88];"				//load bitslice key [3]  only bit "b_4"
  		"ldr r11, [sp, #92];"				//load bitslice key [3]  only bit "b_5"
  		/* XOR each register with the key position bit*/
  		"eor r0, r0, r6;"
  		"eor r1, r1, r7;"
  		"eor r2, r2, r8;"
  		"eor r3, r3, r9;"
  		"eor r4, r4, r10;"
  		"eor r5, r5, r11;"
  		/*EN of ARK*/
  	);

  	asm(/*		Sbox implementation in assembly		*/
  		"and r9, r4, r2;"					//  r9  <= r2 and r4
  		"orn r9, r9, r5;"					//  r9  <= not((r2 and r4) or r5)
  		"and r9, r9, r3;"					//	r9  <= r3 and not((r2 and r4) or r5)
  		"and r10, r5, r4;"					//	r10 <= (r5 and r4)
  		"orn r11, r3, r0;"					//	r11 <= not(r3 or r0)
  		"orn r10, r10, r11;"				//	r10 <= not((r5 and r4) or (not(r3 or r0)))
  		"and r10, r1, r10;"					//	r10 <= (not((r5 and r4) or (not(r3 or r0)))) and (r1)
  		"orr r6, r10, r9;"					//	r6  <= (((not((r5 and r4) or (not(r3 or r0)))) and (r1)) or (r3 and not((r2 and r4) or r5)))

  		"and r9, r0, r2;"					//	r9  <= (r0 and r2)			r9 	overwrite
  		"orn r10, r2, r3;"					//	r10 <= not(r2 or r3)		r10 overwrite
  		"orn r9, r9, r10;"					//	r9	<= not((r0 and r0) or (not(r2 or r3)))
  		"and r9, r9, r5;"					//	r9	<= ((not((r0 and r0) or (not(r2 or r3)))) and r5)
  		"orr r10, r5, r4;"					//	r10 <= (r5 or r4)			r10 overwrite
  		"orn r10, r10, r3;"					//	r10 <= not((not(r5 or r4)) or r3)
  		"orn r9, r9, r10;"					//	r9 	<= not(((not((r0 and r0) or (not(r2 or r3)))) and r5) or (not((not(r5 or r4)) or r3)))
  		"orr r10, r0, r3;"					//	r10 <= (r0 or r3)			r10	overwrite
  		"orn r10, r10, r1;"					//	r10	<= not((r0 or r3) or r1)
  		"orn r7, r9, r10;"					//	r7	<= not((not(((not((r0 and r0) or (not(r2 or r3)))) and r5) or (not((not(r5 or r4)) or r3)))) or (not((r0 or r3) or r1)) )

  		"and r9, r1, r3;"					//	r9 	<= (r1 and r3)			r9	overwrite
  		"orn r10, r3, r4;"					//	r10 <= not(r3 or r4)		r10	overwrite
  		"orn r9, r9, r10;"					//	r9	<= not((not(r3 or r4)) or (r1 and r3))
  		"and r9, r0, r9;"					//	r9	<= ((not((not(r3 or r4)) or (r1 and r3))) and r0)
  		"orr r10, r3, r4;"					//	r10 <= (r3 or r4)			r10	overwrite
  		"orn r10, r10, r2;"					//	r10	<= not((r3 or r4) or r2)
  		"orn r9, r9, r10;"					//	r9	<= not(((not((not(r3 or r4)) or (r1 and r3))) and r0) or (not((r3 or r4) or r2)) )
  		"orr r10, r0, r2;"					//	r10	<= (r0 or r2)			r10	overwrite
  		"orr r10, r10, r5;"					//	r10 <= ((r0 or r2) or r5)
  		"orn r8, r9, r10;"					//	r8	<= not((not(((not((not(r3 or r4)) or (r1 and r3))) and r0) or (not((r3 or r4) or r2)))) or (((r0 or r2) or r5)))

  		"and r9, r0, r4;"					//	r9	<= (r0 and r4)			r9	overwrite
  		"orr r10, r0, r3;"					//	r10	<= (r0 or r3)			r10 overwrite
  		"orn r9, r9, r10;"					//	r9	<= not((r0 and r4) or (r0 or r3))
  		"and r9, r9, r2;"					//	r9	<= ((not((r0 and r4) or (r0 or r3))) and r2)
  		"and r10, r0, r5;"					//	r10 <= (r0 and r5)			r10	overwrite
  		"orn r10, r2, r10;"					//	r10	<= not((r0 and r5) or r2)
  		"orn r9, r9, r10;"					//	r9	<= not(((not((r0 and r4) or (r0 or r3))) and r2) or (not((r0 and r5) or r2)))
  		"and r10, r1, r3;"					//	r10 <= (r1 and r3)			r10 overwrite
  		"orn r10, r0, r10;"					//	r10	<= not((r1 and r3) or r0)
  		"orn r9, r9, r10;"					//	r9	<= not((not(((not((r0 and r4) or (r0 or r3))) and r2) or (not((r0 and r5) or r2)))) or (not((r1 and r3) or r0)))

  		"eor r12, r12, r12;" 		      	//	r12 <= 0's

  		"orr r10, r4, r2;"					//	r10	<= (r4 or r2)
  		"orr r11, r0, r1;"					//	r11 <= (r0 or r1)
  		"orn r10, r10, r11;"				//	r10	<= not((r4 or r2) or (r0 or r1))
  		"orn r10, r12, r10;"				//	r10	<= not(() or (not((r4 or r2) or (r0 or r1))))
  		"orn r11, r3, r0;"					//	r11	<= not( r3 or r0)		r11	overwrite
  		"orn r10, r10, r11;"				//	r10	<= not((not(() or (not((r4 or r2) or (r0 or r1))))) or (not( r3 or r0)))
  		"and r11, r4, r5;"					//	r11	<= (r4 and r5)			r11	overwrite
  		"orn r11, r0, r11;"					//	r11 <= not((r4 and r5) or r0)
  		"orn r10, r10, r11;"				//	r10 <= not((not((not(() or (not((r4 or r2) or (r0 or r1))))) or (not( r3 or r0)))) or (not((r4 and r5) or r0)))

  		"and r12, r0, r3;"					//  r12 <= (r0 and r3)			r12	overwrite
  		"orn r11, r2, r4;"					//	r11	<= not(r2 or r4)		r11	overwrite
  		"orn r12, r12, r11;"				//	r12	<= not(((r0 and r3)) or (not(r2 or r4)))
  		"orn r12, r1, r12;"					//	r12	<= not((not(((r0 and r3)) or (not(r2 or r4)))) or r1)
  		"and r11, r1, r0;"					//	r11	<= (r1 and r0)
  		"orr r11, r11, r5;"					//	r11	<= ((r1 and r0) or r5)
  		"and r11, r11, r2;"					//	r11	<= (((r1 and r0) or r5) and r2)
  		"orn r11, r11, r12;"				//	r11	<= not((((r1 and r0) or r5) and r2) or (not((not(((r0 and r3)) or (not(r2 or r4)))) or r1)))
  		/*		Sbox implementation assembly end	*/
  	);

  	asm(	/* shift columns */
  		"mov r0, r6;"
  		"mov r1, r7, ror #31;"
  		"mov r2, r8, ror #30;"
  		"mov r3, r9, ror #29;"
  		"mov r4, r10, ror #28;"
  		"mov r5, r11, ror #27;"
  		/* shift columns end */
  	);

  	asm(/*		Sbox implementation in assembly		*/
  		"and r9, r4, r2;"					//  r9  <= r2 and r4
  		"orn r9, r9, r5;"					//  r9  <= not((r2 and r4) or r5)
  		"and r9, r9, r3;"					//	r9  <= r3 and not((r2 and r4) or r5)
  		"and r10, r5, r4;"					//	r10 <= (r5 and r4)
  		"orn r11, r3, r0;"					//	r11 <= not(r3 or r0)
  		"orn r10, r10, r11;"				//	r10 <= not((r5 and r4) or (not(r3 or r0)))
  		"and r10, r1, r10;"					//	r10 <= (not((r5 and r4) or (not(r3 or r0)))) and (r1)
  		"orr r6, r10, r9;"					//	r6  <= (((not((r5 and r4) or (not(r3 or r0)))) and (r1)) or (r3 and not((r2 and r4) or r5)))

  		"and r9, r0, r2;"					//	r9  <= (r0 and r2)			r9 	overwrite
  		"orn r10, r2, r3;"					//	r10 <= not(r2 or r3)		r10 overwrite
  		"orn r9, r9, r10;"					//	r9	<= not((r0 and r0) or (not(r2 or r3)))
  		"and r9, r9, r5;"					//	r9	<= ((not((r0 and r0) or (not(r2 or r3)))) and r5)
  		"orr r10, r5, r4;"					//	r10 <= (r5 or r4)			r10 overwrite
  		"orn r10, r10, r3;"					//	r10 <= not((not(r5 or r4)) or r3)
  		"orn r9, r9, r10;"					//	r9 	<= not(((not((r0 and r0) or (not(r2 or r3)))) and r5) or (not((not(r5 or r4)) or r3)))
  		"orr r10, r0, r3;"					//	r10 <= (r0 or r3)			r10	overwrite
  		"orn r10, r10, r1;"					//	r10	<= not((r0 or r3) or r1)
  		"orn r7, r9, r10;"					//	r7	<= not((not(((not((r0 and r0) or (not(r2 or r3)))) and r5) or (not((not(r5 or r4)) or r3)))) or (not((r0 or r3) or r1)) )

  		"and r9, r1, r3;"					//	r9 	<= (r1 and r3)			r9	overwrite
  		"orn r10, r3, r4;"					//	r10 <= not(r3 or r4)		r10	overwrite
  		"orn r9, r9, r10;"					//	r9	<= not((not(r3 or r4)) or (r1 and r3))
  		"and r9, r0, r9;"					//	r9	<= ((not((not(r3 or r4)) or (r1 and r3))) and r0)
  		"orr r10, r3, r4;"					//	r10 <= (r3 or r4)			r10	overwrite
  		"orn r10, r10, r2;"					//	r10	<= not((r3 or r4) or r2)
  		"orn r9, r9, r10;"					//	r9	<= not(((not((not(r3 or r4)) or (r1 and r3))) and r0) or (not((r3 or r4) or r2)) )
  		"orr r10, r0, r2;"					//	r10	<= (r0 or r2)			r10	overwrite
  		"orr r10, r10, r5;"					//	r10 <= ((r0 or r2) or r5)
  		"orn r8, r9, r10;"					//	r8	<= not((not(((not((not(r3 or r4)) or (r1 and r3))) and r0) or (not((r3 or r4) or r2)))) or (((r0 or r2) or r5)))

  		"and r9, r0, r4;"					//	r9	<= (r0 and r4)			r9	overwrite
  		"orr r10, r0, r3;"					//	r10	<= (r0 or r3)			r10 overwrite
  		"orn r9, r9, r10;"					//	r9	<= not((r0 and r4) or (r0 or r3))
  		"and r9, r9, r2;"					//	r9	<= ((not((r0 and r4) or (r0 or r3))) and r2)
  		"and r10, r0, r5;"					//	r10 <= (r0 and r5)			r10	overwrite
  		"orn r10, r2, r10;"					//	r10	<= not((r0 and r5) or r2)
  		"orn r9, r9, r10;"					//	r9	<= not(((not((r0 and r4) or (r0 or r3))) and r2) or (not((r0 and r5) or r2)))
  		"and r10, r1, r3;"					//	r10 <= (r1 and r3)			r10 overwrite
  		"orn r10, r0, r10;"					//	r10	<= not((r1 and r3) or r0)
  		"orn r9, r9, r10;"					//	r9	<= not((not(((not((r0 and r4) or (r0 or r3))) and r2) or (not((r0 and r5) or r2)))) or (not((r1 and r3) or r0)))

  		"eor r12, r12, r12;"  			   	//	r12 <= 0's

  		"orr r10, r4, r2;"					//	r10	<= (r4 or r2)
  		"orr r11, r0, r1;"					//	r11 <= (r0 or r1)
  		"orn r10, r10, r11;"				//	r10	<= not((r4 or r2) or (r0 or r1))
  		"orn r10, r12, r10;"				//	r10	<= not(() or (not((r4 or r2) or (r0 or r1))))
  		"orn r11, r3, r0;"					//	r11	<= not( r3 or r0)		r11	overwrite
  		"orn r10, r10, r11;"				//	r10	<= not((not(() or (not((r4 or r2) or (r0 or r1))))) or (not( r3 or r0)))
  		"and r11, r4, r5;"					//	r11	<= (r4 and r5)			r11	overwrite
  		"orn r11, r0, r11;"					//	r11 <= not((r4 and r5) or r0)
  		"orn r10, r10, r11;"				//	r10 <= not((not((not(() or (not((r4 or r2) or (r0 or r1))))) or (not( r3 or r0)))) or (not((r4 and r5) or r0)))

  		"and r12, r0, r3;"					//  r12 <= (r0 and r3)			r12	overwrite
  		"orn r11, r2, r4;"					//	r11	<= not(r2 or r4)		r11	overwrite
  		"orn r12, r12, r11;"				//	r12	<= not(((r0 and r3)) or (not(r2 or r4)))
  		"orn r12, r1, r12;"					//	r12	<= not((not(((r0 and r3)) or (not(r2 or r4)))) or r1)
  		"and r11, r1, r0;"					//	r11	<= (r1 and r0)
  		"orr r11, r11, r5;"					//	r11	<= ((r1 and r0) or r5)
  		"and r11, r11, r2;"					//	r11	<= (((r1 and r0) or r5) and r2)
  		"orn r11, r11, r12;"				//	r11	<= not((((r1 and r0) or r5) and r2) or (not((not(((r0 and r3)) or (not(r2 or r4)))) or r1)))
  		/*		Sbox implementation assembly end	*/
  	);

  	asm(	/* shift columns */
  		"mov r0, r6;"
  		"mov r1, r7, ror #31;"
  		"mov r2, r8, ror #30;"
  		"mov r3, r9, ror #29;"
  		"mov r4, r10, ror #28;"
  		"mov r5, r11, ror #27;"
  		/* shift columns end */
  	);

  	asm(	/* mix columns*/
  		"eor r0, r0, r6, ror #31;" 			//here the mix columns for the r0 register is calculated
  		"eor r0, r0, r6, ror #27;"
  		"eor r0, r0, r6, ror #23;"
  		"eor r0, r0, r6, ror #17;"
  		"eor r0, r0, r6, ror #11;"
  		"eor r0, r0, r6, ror #6;"

  		"eor r1, r1, r7, ror #30;"			//mix columns for the r1 register is calculated
  		"eor r1, r1, r7, ror #26;"
  		"eor r1, r1, r7, ror #22;"
  		"eor r1, r1, r7, ror #16;"
  		"eor r1, r1, r7, ror #10;"
  		"eor r1, r1, r7, ror #5;"

  		"eor r2, r2, r8, ror #29;"			//mix columns for the r2 register is calculated
  		"eor r2, r2, r8, ror #25;"
  		"eor r2, r2, r8, ror #21;"
  		"eor r2, r2, r8, ror #15;"
  		"eor r2, r2, r8, ror #9;"
  		"eor r2, r2, r8, ror #4;"

  		"eor r3, r3, r9, ror #28;"			//mix columns for the r3 register is calculated
  		"eor r3, r3, r9, ror #24;"
  		"eor r3, r3, r9, ror #20;"
  		"eor r3, r3, r9, ror #14;"
  		"eor r3, r3, r9, ror #8;"
  		"eor r3, r3, r9, ror #3;"

  		"eor r4, r4, r10, ror #27;"			//mix columns for the r4 register is calculated
  		"eor r4, r4, r10, ror #23;"
  		"eor r4, r4, r10, ror #19;"
  		"eor r4, r4, r10, ror #13;"
  		"eor r4, r4, r10, ror #7;"
  		"eor r4, r4, r10, ror #2;"

  		"eor r5, r5, r11, ror #26;"			//mix columns for the r5 register is calculated
  		"eor r5, r5, r11, ror #22;"
  		"eor r5, r5, r11, ror #18;"
  		"eor r5, r5, r11, ror #12;"
  		"eor r5, r5, r11, ror #6;"
  		"eor r5, r5, r11, ror #1;"
  		/* mix columns end*/
  );

  asm(	/*		Round constants in bitslice representation		*/
  		/*		register from r6 to r12 haven't valid data erase them	*/
  		"mov 	r6, 0XAFF6;"				//move the round constant low part in bitslice representation	bit 0
  		"movt	r6, 0X8EB8;"				//move the round constant high part in bitslice representation  bit 0
  		"mov	r7, 0X9463;"				//move the round constant low part in bitslice representation   bit 1
  		"movt	r7, 0XC16D;"				//move the round constant high part in bitslice representation  bit 1
  		"mov	r8, 0X3CDA;"				//move the round constant low part in bitslice representation	bit 2
  		"movt	r8, 0X1DDB;"				//move the round constant high part in bitslice representation  bit 2
  		"mov	r9, 0X9865;"				//move the round constant low part in bitslice representation	bit 3
  		"movt	r9, 0XA19C;"				//move the round constant high part in bitslice representation  bit 3
  		"mov	r10, 0X36D7;"				//move the round constant low part in bitslice representation	bit 4
  		"movt	r10, 0X535F;"				//move the round constant high part in bitslice representation  bit 4
  		"mov	r11, 0X7FAC;"				//move the round constant low part in bitslice representation	bit 5
  		"movt   r11, 0X5F9F;"				//move the round constant high part in bitslice representation  bit 5
  		/*		add round constant to the state i.e. blk i xor constant i		*/
  		"eor r0, r0, r6;"
  		"eor r1, r1, r7;"
  		"eor r2, r2, r8;"
  		"eor r3, r3, r9;"
  		"eor r4, r4, r10;"
  		"eor r5, r5, r11;"
  		"eor r12, r12;"
  	);
  	/*at this point the 3rd round is done the results are in r0 - r5 then r6 - r12 can be clean*/

  ///////////// round  4 //////////////
  	asm(/*	ARK	 the key must be in bitslice*/
  		"ldr r6, [sp, #96];"				//load bitslice key [4]  only bit "b_0"
  		"ldr r7, [sp, #100];"				//load bitslice key [4]  only bit "b_1"
  		"ldr r8, [sp, #104];"				//load bitslice key [4]  only bit "b_2"
  		"ldr r9, [sp, #108];"				//load bitslice key [4]  only bit "b_3"
  		"ldr r10, [sp, #112];"				//load bitslice key [4]  only bit "b_4"
  		"ldr r11, [sp, #116];"				//load bitslice key [4]  only bit "b_5"
  /* XOR each register with the key position bit*/
  		"eor r0, r0, r6;"
  		"eor r1, r1, r7;"
  		"eor r2, r2, r8;"
  		"eor r3, r3, r9;"
  		"eor r4, r4, r10;"
  		"eor r5, r5, r11;"
  		/*EN of ARK*/
  	);

  	asm(	/*		Sbox implementation in assembly		*/
  		"and r9, r4, r2;"					//  r9  <= r2 and r4
  		"orn r9, r9, r5;"					//  r9  <= not((r2 and r4) or r5)
  		"and r9, r9, r3;"					//	r9  <= r3 and not((r2 and r4) or r5)
  		"and r10, r5, r4;"					//	r10 <= (r5 and r4)
  		"orn r11, r3, r0;"					//	r11 <= not(r3 or r0)
  		"orn r10, r10, r11;"				//	r10 <= not((r5 and r4) or (not(r3 or r0)))
  		"and r10, r1, r10;"					//	r10 <= (not((r5 and r4) or (not(r3 or r0)))) and (r1)
  		"orr r6, r10, r9;"					//	r6  <= (((not((r5 and r4) or (not(r3 or r0)))) and (r1)) or (r3 and not((r2 and r4) or r5)))

  		"and r9, r0, r2;"					//	r9  <= (r0 and r2)			r9 	overwrite
  		"orn r10, r2, r3;"					//	r10 <= not(r2 or r3)		r10 overwrite
  		"orn r9, r9, r10;"					//	r9	<= not((r0 and r0) or (not(r2 or r3)))
  		"and r9, r9, r5;"					//	r9	<= ((not((r0 and r0) or (not(r2 or r3)))) and r5)
  		"orr r10, r5, r4;"					//	r10 <= (r5 or r4)			r10 overwrite
  		"orn r10, r10, r3;"					//	r10 <= not((not(r5 or r4)) or r3)
  		"orn r9, r9, r10;"					//	r9 	<= not(((not((r0 and r0) or (not(r2 or r3)))) and r5) or (not((not(r5 or r4)) or r3)))
  		"orr r10, r0, r3;"					//	r10 <= (r0 or r3)			r10	overwrite
  		"orn r10, r10, r1;"					//	r10	<= not((r0 or r3) or r1)
  		"orn r7, r9, r10;"					//	r7	<= not((not(((not((r0 and r0) or (not(r2 or r3)))) and r5) or (not((not(r5 or r4)) or r3)))) or (not((r0 or r3) or r1)) )

  		"and r9, r1, r3;"					//	r9 	<= (r1 and r3)			r9	overwrite
  		"orn r10, r3, r4;"					//	r10 <= not(r3 or r4)		r10	overwrite
  		"orn r9, r9, r10;"					//	r9	<= not((not(r3 or r4)) or (r1 and r3))
  		"and r9, r0, r9;"					//	r9	<= ((not((not(r3 or r4)) or (r1 and r3))) and r0)
  		"orr r10, r3, r4;"					//	r10 <= (r3 or r4)			r10	overwrite
  		"orn r10, r10, r2;"					//	r10	<= not((r3 or r4) or r2)
  		"orn r9, r9, r10;"					//	r9	<= not(((not((not(r3 or r4)) or (r1 and r3))) and r0) or (not((r3 or r4) or r2)) )
  		"orr r10, r0, r2;"					//	r10	<= (r0 or r2)			r10	overwrite
  		"orr r10, r10, r5;"					//	r10 <= ((r0 or r2) or r5)
  		"orn r8, r9, r10;"					//	r8	<= not((not(((not((not(r3 or r4)) or (r1 and r3))) and r0) or (not((r3 or r4) or r2)))) or (((r0 or r2) or r5)))

  		"and r9, r0, r4;"					//	r9	<= (r0 and r4)			r9	overwrite
  		"orr r10, r0, r3;"					//	r10	<= (r0 or r3)			r10 overwrite
  		"orn r9, r9, r10;"					//	r9	<= not((r0 and r4) or (r0 or r3))
  		"and r9, r9, r2;"					//	r9	<= ((not((r0 and r4) or (r0 or r3))) and r2)
  		"and r10, r0, r5;"					//	r10 <= (r0 and r5)			r10	overwrite
  		"orn r10, r2, r10;"					//	r10	<= not((r0 and r5) or r2)
  		"orn r9, r9, r10;"					//	r9	<= not(((not((r0 and r4) or (r0 or r3))) and r2) or (not((r0 and r5) or r2)))
  		"and r10, r1, r3;"					//	r10 <= (r1 and r3)			r10 overwrite
  		"orn r10, r0, r10;"					//	r10	<= not((r1 and r3) or r0)
  		"orn r9, r9, r10;"					//	r9	<= not((not(((not((r0 and r4) or (r0 or r3))) and r2) or (not((r0 and r5) or r2)))) or (not((r1 and r3) or r0)))

  		"eor r12, r12, r12;"  		     	//	r12 <= 0's

  		"orr r10, r4, r2;"					//	r10	<= (r4 or r2)
  		"orr r11, r0, r1;"					//	r11 <= (r0 or r1)
  		"orn r10, r10, r11;"				//	r10	<= not((r4 or r2) or (r0 or r1))
  		"orn r10, r12, r10;"				//	r10	<= not(() or (not((r4 or r2) or (r0 or r1))))
  		"orn r11, r3, r0;"					//	r11	<= not( r3 or r0)		r11	overwrite
  		"orn r10, r10, r11;"				//	r10	<= not((not(() or (not((r4 or r2) or (r0 or r1))))) or (not( r3 or r0)))
  		"and r11, r4, r5;"					//	r11	<= (r4 and r5)			r11	overwrite
  		"orn r11, r0, r11;"					//	r11 <= not((r4 and r5) or r0)
  		"orn r10, r10, r11;"				//	r10 <= not((not((not(() or (not((r4 or r2) or (r0 or r1))))) or (not( r3 or r0)))) or (not((r4 and r5) or r0)))

  		"and r12, r0, r3;"					//  r12 <= (r0 and r3)			r12	overwrite
  		"orn r11, r2, r4;"					//	r11	<= not(r2 or r4)		r11	overwrite
  		"orn r12, r12, r11;"				//	r12	<= not(((r0 and r3)) or (not(r2 or r4)))
  		"orn r12, r1, r12;"					//	r12	<= not((not(((r0 and r3)) or (not(r2 or r4)))) or r1)
  		"and r11, r1, r0;"					//	r11	<= (r1 and r0)
  		"orr r11, r11, r5;"					//	r11	<= ((r1 and r0) or r5)
  		"and r11, r11, r2;"					//	r11	<= (((r1 and r0) or r5) and r2)
  		"orn r11, r11, r12;"				//	r11	<= not((((r1 and r0) or r5) and r2) or (not((not(((r0 and r3)) or (not(r2 or r4)))) or r1)))
  		/*		Sbox implementation assembly end	*/
  	);

  	asm(	/* shift columns */
  		"mov r0, r6;"
  		"mov r1, r7, ror #31;"
  		"mov r2, r8, ror #30;"
  		"mov r3, r9, ror #29;"
  		"mov r4, r10, ror #28;"
  		"mov r5, r11, ror #27;"
  		/* shift columns end */
  	);

  	asm(/*		Sbox implementation in assembly		*/
  		"and r9, r4, r2;"					//  r9  <= r2 and r4
  		"orn r9, r9, r5;"					//  r9  <= not((r2 and r4) or r5)
  		"and r9, r9, r3;"					//	r9  <= r3 and not((r2 and r4) or r5)
  		"and r10, r5, r4;"					//	r10 <= (r5 and r4)
  		"orn r11, r3, r0;"					//	r11 <= not(r3 or r0)
  		"orn r10, r10, r11;"				//	r10 <= not((r5 and r4) or (not(r3 or r0)))
  		"and r10, r1, r10;"					//	r10 <= (not((r5 and r4) or (not(r3 or r0)))) and (r1)
  		"orr r6, r10, r9;"					//	r6  <= (((not((r5 and r4) or (not(r3 or r0)))) and (r1)) or (r3 and not((r2 and r4) or r5)))

  		"and r9, r0, r2;"					//	r9  <= (r0 and r2)			r9 	overwrite
  		"orn r10, r2, r3;"					//	r10 <= not(r2 or r3)		r10 overwrite
  		"orn r9, r9, r10;"					//	r9	<= not((r0 and r0) or (not(r2 or r3)))
  		"and r9, r9, r5;"					//	r9	<= ((not((r0 and r0) or (not(r2 or r3)))) and r5)
  		"orr r10, r5, r4;"					//	r10 <= (r5 or r4)			r10 overwrite
  		"orn r10, r10, r3;"					//	r10 <= not((not(r5 or r4)) or r3)
  		"orn r9, r9, r10;"					//	r9 	<= not(((not((r0 and r0) or (not(r2 or r3)))) and r5) or (not((not(r5 or r4)) or r3)))
  		"orr r10, r0, r3;"					//	r10 <= (r0 or r3)			r10	overwrite
  		"orn r10, r10, r1;"					//	r10	<= not((r0 or r3) or r1)
  		"orn r7, r9, r10;"					//	r7	<= not((not(((not((r0 and r0) or (not(r2 or r3)))) and r5) or (not((not(r5 or r4)) or r3)))) or (not((r0 or r3) or r1)) )

  		"and r9, r1, r3;"					//	r9 	<= (r1 and r3)			r9	overwrite
  		"orn r10, r3, r4;"					//	r10 <= not(r3 or r4)		r10	overwrite
  		"orn r9, r9, r10;"					//	r9	<= not((not(r3 or r4)) or (r1 and r3))
  		"and r9, r0, r9;"					//	r9	<= ((not((not(r3 or r4)) or (r1 and r3))) and r0)
  		"orr r10, r3, r4;"					//	r10 <= (r3 or r4)			r10	overwrite
  		"orn r10, r10, r2;"					//	r10	<= not((r3 or r4) or r2)
  		"orn r9, r9, r10;"					//	r9	<= not(((not((not(r3 or r4)) or (r1 and r3))) and r0) or (not((r3 or r4) or r2)) )
  		"orr r10, r0, r2;"					//	r10	<= (r0 or r2)			r10	overwrite
  		"orr r10, r10, r5;"					//	r10 <= ((r0 or r2) or r5)
  		"orn r8, r9, r10;"					//	r8	<= not((not(((not((not(r3 or r4)) or (r1 and r3))) and r0) or (not((r3 or r4) or r2)))) or (((r0 or r2) or r5)))

  		"and r9, r0, r4;"					//	r9	<= (r0 and r4)			r9	overwrite
  		"orr r10, r0, r3;"					//	r10	<= (r0 or r3)			r10 overwrite
  		"orn r9, r9, r10;"					//	r9	<= not((r0 and r4) or (r0 or r3))
  		"and r9, r9, r2;"					//	r9	<= ((not((r0 and r4) or (r0 or r3))) and r2)
  		"and r10, r0, r5;"					//	r10 <= (r0 and r5)			r10	overwrite
  		"orn r10, r2, r10;"					//	r10	<= not((r0 and r5) or r2)
  		"orn r9, r9, r10;"					//	r9	<= not(((not((r0 and r4) or (r0 or r3))) and r2) or (not((r0 and r5) or r2)))
  		"and r10, r1, r3;"					//	r10 <= (r1 and r3)			r10 overwrite
  		"orn r10, r0, r10;"					//	r10	<= not((r1 and r3) or r0)
  		"orn r9, r9, r10;"					//	r9	<= not((not(((not((r0 and r4) or (r0 or r3))) and r2) or (not((r0 and r5) or r2)))) or (not((r1 and r3) or r0)))

  		"eor r12, r12, r12;" 			   	//	r12 <= 0's

  		"orr r10, r4, r2;"					//	r10	<= (r4 or r2)
  		"orr r11, r0, r1;"					//	r11 <= (r0 or r1)
  		"orn r10, r10, r11;"				//	r10	<= not((r4 or r2) or (r0 or r1))
  		"orn r10, r12, r10;"				//	r10	<= not(() or (not((r4 or r2) or (r0 or r1))))
  		"orn r11, r3, r0;"					//	r11	<= not( r3 or r0)		r11	overwrite
  		"orn r10, r10, r11;"				//	r10	<= not((not(() or (not((r4 or r2) or (r0 or r1))))) or (not( r3 or r0)))
  		"and r11, r4, r5;"					//	r11	<= (r4 and r5)			r11	overwrite
  		"orn r11, r0, r11;"					//	r11 <= not((r4 and r5) or r0)
  		"orn r10, r10, r11;"				//	r10 <= not((not((not(() or (not((r4 or r2) or (r0 or r1))))) or (not( r3 or r0)))) or (not((r4 and r5) or r0)))

  		"and r12, r0, r3;"					//  r12 <= (r0 and r3)			r12	overwrite
  		"orn r11, r2, r4;"					//	r11	<= not(r2 or r4)		r11	overwrite
  		"orn r12, r12, r11;"				//	r12	<= not(((r0 and r3)) or (not(r2 or r4)))
  		"orn r12, r1, r12;"					//	r12	<= not((not(((r0 and r3)) or (not(r2 or r4)))) or r1)
  		"and r11, r1, r0;"					//	r11	<= (r1 and r0)
  		"orr r11, r11, r5;"					//	r11	<= ((r1 and r0) or r5)
  		"and r11, r11, r2;"					//	r11	<= (((r1 and r0) or r5) and r2)
  		"orn r11, r11, r12;"				//	r11	<= not((((r1 and r0) or r5) and r2) or (not((not(((r0 and r3)) or (not(r2 or r4)))) or r1)))
  		/*		Sbox implementation assembly end	*/
  	);

  	asm(	/* shift columns */
  		"mov r0, r6;"
  		"mov r1, r7, ror #31;"
  		"mov r2, r8, ror #30;"
  		"mov r3, r9, ror #29;"
  		"mov r4, r10, ror #28;"
  		"mov r5, r11, ror #27;"
  		/* shift columns end */
  	);

  	asm(	/* mix columns*/
  		"eor r0, r0, r6, ror #31;" 			//here the mix columns for the r0 register is calculated
  		"eor r0, r0, r6, ror #27;"
  		"eor r0, r0, r6, ror #23;"
  		"eor r0, r0, r6, ror #17;"
  		"eor r0, r0, r6, ror #11;"
  		"eor r0, r0, r6, ror #6;"

  		"eor r1, r1, r7, ror #30;"			//mix columns for the r1 register is calculated
  		"eor r1, r1, r7, ror #26;"
  		"eor r1, r1, r7, ror #22;"
  		"eor r1, r1, r7, ror #16;"
  		"eor r1, r1, r7, ror #10;"
  		"eor r1, r1, r7, ror #5;"

  		"eor r2, r2, r8, ror #29;"			//mix columns for the r2 register is calculated
  		"eor r2, r2, r8, ror #25;"
  		"eor r2, r2, r8, ror #21;"
  		"eor r2, r2, r8, ror #15;"
  		"eor r2, r2, r8, ror #9;"
  		"eor r2, r2, r8, ror #4;"

  		"eor r3, r3, r9, ror #28;"			//mix columns for the r3 register is calculated
  		"eor r3, r3, r9, ror #24;"
  		"eor r3, r3, r9, ror #20;"
  		"eor r3, r3, r9, ror #14;"
  		"eor r3, r3, r9, ror #8;"
  		"eor r3, r3, r9, ror #3;"

  		"eor r4, r4, r10, ror #27;"			//mix columns for the r4 register is calculated
  		"eor r4, r4, r10, ror #23;"
  		"eor r4, r4, r10, ror #19;"
  		"eor r4, r4, r10, ror #13;"
  		"eor r4, r4, r10, ror #7;"
  		"eor r4, r4, r10, ror #2;"

  		"eor r5, r5, r11, ror #26;"			//mix columns for the r5 register is calculated
  		"eor r5, r5, r11, ror #22;"
  		"eor r5, r5, r11, ror #18;"
  		"eor r5, r5, r11, ror #12;"
  		"eor r5, r5, r11, ror #6;"
  		"eor r5, r5, r11, ror #1;"
  		/* mix columns end*/
  	);

  	asm(	/*		Round constants in bitslice representation		*/
  		/*		register from r6 to r12 haven't valid data erase them	*/
  		"mov 	r6, 0XDECE;"				//move the round constant low part in bitslice representation	bit 0
  		"movt	r6, 0XE17A;"				//move the round constant high part in bitslice representation  bit 0
  		"mov	r7, 0X4C83;"				//move the round constant low part in bitslice representation   bit 1
  		"movt	r7, 0X3CC4;"				//move the round constant high part in bitslice representation  bit 1
  		"mov	r8, 0XD8E4;"				//move the round constant low part in bitslice representation	bit 2
  		"movt	r8, 0X85CC;"				//move the round constant high part in bitslice representation  bit 2
  		"mov	r9, 0XB8D5;"				//move the round constant low part in bitslice representation	bit 3
  		"movt	r9, 0XC7B3;"				//move the round constant high part in bitslice representation  bit 3
  		"mov	r10, 0X006D;"				//move the round constant low part in bitslice representation	bit 4
  		"movt	r10, 0XE481;"				//move the round constant high part in bitslice representation  bit 4
  		"mov	r11, 0X691C;"				//move the round constant low part in bitslice representation	bit 5
  		"movt   r11, 0X4CC7;"				//move the round constant high part in bitslice representation  bit 5
  		/*		add round constant to the state i.e. blk i xor constant i		*/
  		"eor r0, r0, r6;"
  		"eor r1, r1, r7;"
  		"eor r2, r2, r8;"
  		"eor r3, r3, r9;"
  		"eor r4, r4, r10;"
  		"eor r5, r5, r11;"
  		"eor r12, r12;"
  	);
  	/*at this point the 4th round is done the results are in r0 - r5 then r6 - r12 can be clean*/

  ///////////// round  5 //////////////
  	asm(	/*	ARK	 the key must be in bitslice*/
  		"ldr r6, [sp, #120];"				//load bitslice key [5]  only bit "b_0"
  		"ldr r7, [sp, #124];"				//load bitslice key [5]  only bit "b_1"
  		"ldr r8, [sp, #128];"				//load bitslice key [5]  only bit "b_2"
  		"ldr r9, [sp, #132];"				//load bitslice key [5]  only bit "b_3"
  		"ldr r10, [sp, #136];"				//load bitslice key [5]  only bit "b_4"
  		"ldr r11, [sp, #140];"				//load bitslice key [5]  only bit "b_5"
  			/* XOR each register with the key position bit*/
  		"eor r0, r0, r6;"
  		"eor r1, r1, r7;"
  		"eor r2, r2, r8;"
  		"eor r3, r3, r9;"
  		"eor r4, r4, r10;"
  		"eor r5, r5, r11;"
  		/*EN of ARK*/
  	);

  	asm(	/*		Sbox implementation in assembly		*/
  		"and r9, r4, r2;"					//  r9  <= r2 and r4
  		"orn r9, r9, r5;"					//  r9  <= not((r2 and r4) or r5)
  		"and r9, r9, r3;"					//	r9  <= r3 and not((r2 and r4) or r5)
  		"and r10, r5, r4;"					//	r10 <= (r5 and r4)
  		"orn r11, r3, r0;"					//	r11 <= not(r3 or r0)
  		"orn r10, r10, r11;"				//	r10 <= not((r5 and r4) or (not(r3 or r0)))
  		"and r10, r1, r10;"					//	r10 <= (not((r5 and r4) or (not(r3 or r0)))) and (r1)
  		"orr r6, r10, r9;"					//	r6  <= (((not((r5 and r4) or (not(r3 or r0)))) and (r1)) or (r3 and not((r2 and r4) or r5)))

  		"and r9, r0, r2;"					//	r9  <= (r0 and r2)			r9 	overwrite
  		"orn r10, r2, r3;"					//	r10 <= not(r2 or r3)		r10 overwrite
  		"orn r9, r9, r10;"					//	r9	<= not((r0 and r0) or (not(r2 or r3)))
  		"and r9, r9, r5;"					//	r9	<= ((not((r0 and r0) or (not(r2 or r3)))) and r5)
  		"orr r10, r5, r4;"					//	r10 <= (r5 or r4)			r10 overwrite
  		"orn r10, r10, r3;"					//	r10 <= not((not(r5 or r4)) or r3)
  		"orn r9, r9, r10;"					//	r9 	<= not(((not((r0 and r0) or (not(r2 or r3)))) and r5) or (not((not(r5 or r4)) or r3)))
  		"orr r10, r0, r3;"					//	r10 <= (r0 or r3)			r10	overwrite
  		"orn r10, r10, r1;"					//	r10	<= not((r0 or r3) or r1)
  		"orn r7, r9, r10;"					//	r7	<= not((not(((not((r0 and r0) or (not(r2 or r3)))) and r5) or (not((not(r5 or r4)) or r3)))) or (not((r0 or r3) or r1)) )

  		"and r9, r1, r3;"					//	r9 	<= (r1 and r3)			r9	overwrite
  		"orn r10, r3, r4;"					//	r10 <= not(r3 or r4)		r10	overwrite
  		"orn r9, r9, r10;"					//	r9	<= not((not(r3 or r4)) or (r1 and r3))
  		"and r9, r0, r9;"					//	r9	<= ((not((not(r3 or r4)) or (r1 and r3))) and r0)
  		"orr r10, r3, r4;"					//	r10 <= (r3 or r4)			r10	overwrite
  		"orn r10, r10, r2;"					//	r10	<= not((r3 or r4) or r2)
  		"orn r9, r9, r10;"					//	r9	<= not(((not((not(r3 or r4)) or (r1 and r3))) and r0) or (not((r3 or r4) or r2)) )
  		"orr r10, r0, r2;"					//	r10	<= (r0 or r2)			r10	overwrite
  		"orr r10, r10, r5;"					//	r10 <= ((r0 or r2) or r5)
  		"orn r8, r9, r10;"					//	r8	<= not((not(((not((not(r3 or r4)) or (r1 and r3))) and r0) or (not((r3 or r4) or r2)))) or (((r0 or r2) or r5)))

  		"and r9, r0, r4;"					//	r9	<= (r0 and r4)			r9	overwrite
  		"orr r10, r0, r3;"					//	r10	<= (r0 or r3)			r10 overwrite
  		"orn r9, r9, r10;"					//	r9	<= not((r0 and r4) or (r0 or r3))
  		"and r9, r9, r2;"					//	r9	<= ((not((r0 and r4) or (r0 or r3))) and r2)
  		"and r10, r0, r5;"					//	r10 <= (r0 and r5)			r10	overwrite
  		"orn r10, r2, r10;"					//	r10	<= not((r0 and r5) or r2)
  		"orn r9, r9, r10;"					//	r9	<= not(((not((r0 and r4) or (r0 or r3))) and r2) or (not((r0 and r5) or r2)))
  		"and r10, r1, r3;"					//	r10 <= (r1 and r3)			r10 overwrite
  		"orn r10, r0, r10;"					//	r10	<= not((r1 and r3) or r0)
  		"orn r9, r9, r10;"					//	r9	<= not((not(((not((r0 and r4) or (r0 or r3))) and r2) or (not((r0 and r5) or r2)))) or (not((r1 and r3) or r0)))

  		"eor r12, r12, r12;"				//	r12 <= 0's

  		"orr r10, r4, r2;"					//	r10	<= (r4 or r2)
  		"orr r11, r0, r1;"					//	r11 <= (r0 or r1)
  		"orn r10, r10, r11;"				//	r10	<= not((r4 or r2) or (r0 or r1))
  		"orn r10, r12, r10;"				//	r10	<= not(() or (not((r4 or r2) or (r0 or r1))))
  		"orn r11, r3, r0;"					//	r11	<= not( r3 or r0)		r11	overwrite
  		"orn r10, r10, r11;"				//	r10	<= not((not(() or (not((r4 or r2) or (r0 or r1))))) or (not( r3 or r0)))
  		"and r11, r4, r5;"					//	r11	<= (r4 and r5)			r11	overwrite
  		"orn r11, r0, r11;"					//	r11 <= not((r4 and r5) or r0)
  		"orn r10, r10, r11;"				//	r10 <= not((not((not(() or (not((r4 or r2) or (r0 or r1))))) or (not( r3 or r0)))) or (not((r4 and r5) or r0)))

  		"and r12, r0, r3;"					//  r12 <= (r0 and r3)			r12	overwrite
  		"orn r11, r2, r4;"					//	r11	<= not(r2 or r4)		r11	overwrite
  		"orn r12, r12, r11;"				//	r12	<= not(((r0 and r3)) or (not(r2 or r4)))
  		"orn r12, r1, r12;"					//	r12	<= not((not(((r0 and r3)) or (not(r2 or r4)))) or r1)
  		"and r11, r1, r0;"					//	r11	<= (r1 and r0)
  		"orr r11, r11, r5;"					//	r11	<= ((r1 and r0) or r5)
  		"and r11, r11, r2;"					//	r11	<= (((r1 and r0) or r5) and r2)
  		"orn r11, r11, r12;"				//	r11	<= not((((r1 and r0) or r5) and r2) or (not((not(((r0 and r3)) or (not(r2 or r4)))) or r1)))
  		/*		Sbox implementation assembly end	*/
  	);

  	asm(	/* shift columns */
  		"mov r0, r6;"
  		"mov r1, r7, ror #31;"
  		"mov r2, r8, ror #30;"
  		"mov r3, r9, ror #29;"
  		"mov r4, r10, ror #28;"
  		"mov r5, r11, ror #27;"
  		/* shift columns end */
  	);

  	asm(/*		Sbox implementation in assembly		*/
  		"and r9, r4, r2;"					//  r9  <= r2 and r4
  		"orn r9, r9, r5;"					//  r9  <= not((r2 and r4) or r5)
  		"and r9, r9, r3;"					//	r9  <= r3 and not((r2 and r4) or r5)
  		"and r10, r5, r4;"					//	r10 <= (r5 and r4)
  		"orn r11, r3, r0;"					//	r11 <= not(r3 or r0)
  		"orn r10, r10, r11;"				//	r10 <= not((r5 and r4) or (not(r3 or r0)))
  		"and r10, r1, r10;"					//	r10 <= (not((r5 and r4) or (not(r3 or r0)))) and (r1)
  		"orr r6, r10, r9;"					//	r6  <= (((not((r5 and r4) or (not(r3 or r0)))) and (r1)) or (r3 and not((r2 and r4) or r5)))

  		"and r9, r0, r2;"					//	r9  <= (r0 and r2)			r9 	overwrite
  		"orn r10, r2, r3;"					//	r10 <= not(r2 or r3)		r10 overwrite
  		"orn r9, r9, r10;"					//	r9	<= not((r0 and r0) or (not(r2 or r3)))
  		"and r9, r9, r5;"					//	r9	<= ((not((r0 and r0) or (not(r2 or r3)))) and r5)
  		"orr r10, r5, r4;"					//	r10 <= (r5 or r4)			r10 overwrite
  		"orn r10, r10, r3;"					//	r10 <= not((not(r5 or r4)) or r3)
  		"orn r9, r9, r10;"					//	r9 	<= not(((not((r0 and r0) or (not(r2 or r3)))) and r5) or (not((not(r5 or r4)) or r3)))
  		"orr r10, r0, r3;"					//	r10 <= (r0 or r3)			r10	overwrite
  		"orn r10, r10, r1;"					//	r10	<= not((r0 or r3) or r1)
  		"orn r7, r9, r10;"					//	r7	<= not((not(((not((r0 and r0) or (not(r2 or r3)))) and r5) or (not((not(r5 or r4)) or r3)))) or (not((r0 or r3) or r1)) )

  		"and r9, r1, r3;"					//	r9 	<= (r1 and r3)			r9	overwrite
  		"orn r10, r3, r4;"					//	r10 <= not(r3 or r4)		r10	overwrite
  		"orn r9, r9, r10;"					//	r9	<= not((not(r3 or r4)) or (r1 and r3))
  		"and r9, r0, r9;"					//	r9	<= ((not((not(r3 or r4)) or (r1 and r3))) and r0)
  		"orr r10, r3, r4;"					//	r10 <= (r3 or r4)			r10	overwrite
  		"orn r10, r10, r2;"					//	r10	<= not((r3 or r4) or r2)
  		"orn r9, r9, r10;"					//	r9	<= not(((not((not(r3 or r4)) or (r1 and r3))) and r0) or (not((r3 or r4) or r2)) )
  		"orr r10, r0, r2;"					//	r10	<= (r0 or r2)			r10	overwrite
  		"orr r10, r10, r5;"					//	r10 <= ((r0 or r2) or r5)
  		"orn r8, r9, r10;"					//	r8	<= not((not(((not((not(r3 or r4)) or (r1 and r3))) and r0) or (not((r3 or r4) or r2)))) or (((r0 or r2) or r5)))

  		"and r9, r0, r4;"					//	r9	<= (r0 and r4)			r9	overwrite
  		"orr r10, r0, r3;"					//	r10	<= (r0 or r3)			r10 overwrite
  		"orn r9, r9, r10;"					//	r9	<= not((r0 and r4) or (r0 or r3))
  		"and r9, r9, r2;"					//	r9	<= ((not((r0 and r4) or (r0 or r3))) and r2)
  		"and r10, r0, r5;"					//	r10 <= (r0 and r5)			r10	overwrite
  		"orn r10, r2, r10;"					//	r10	<= not((r0 and r5) or r2)
  		"orn r9, r9, r10;"					//	r9	<= not(((not((r0 and r4) or (r0 or r3))) and r2) or (not((r0 and r5) or r2)))
  		"and r10, r1, r3;"					//	r10 <= (r1 and r3)			r10 overwrite
  		"orn r10, r0, r10;"					//	r10	<= not((r1 and r3) or r0)
  		"orn r9, r9, r10;"					//	r9	<= not((not(((not((r0 and r4) or (r0 or r3))) and r2) or (not((r0 and r5) or r2)))) or (not((r1 and r3) or r0)))

  		"eor r12, r12, r12;" 		    	//	r12 <= 0's

  		"orr r10, r4, r2;"					//	r10	<= (r4 or r2)
  		"orr r11, r0, r1;"					//	r11 <= (r0 or r1)
  		"orn r10, r10, r11;"				//	r10	<= not((r4 or r2) or (r0 or r1))
  		"orn r10, r12, r10;"				//	r10	<= not(() or (not((r4 or r2) or (r0 or r1))))
  		"orn r11, r3, r0;"					//	r11	<= not( r3 or r0)		r11	overwrite
  		"orn r10, r10, r11;"				//	r10	<= not((not(() or (not((r4 or r2) or (r0 or r1))))) or (not( r3 or r0)))
  		"and r11, r4, r5;"					//	r11	<= (r4 and r5)			r11	overwrite
  		"orn r11, r0, r11;"					//	r11 <= not((r4 and r5) or r0)
  		"orn r10, r10, r11;"				//	r10 <= not((not((not(() or (not((r4 or r2) or (r0 or r1))))) or (not( r3 or r0)))) or (not((r4 and r5) or r0)))

  		"and r12, r0, r3;"					//  r12 <= (r0 and r3)			r12	overwrite
  		"orn r11, r2, r4;"					//	r11	<= not(r2 or r4)		r11	overwrite
  		"orn r12, r12, r11;"				//	r12	<= not(((r0 and r3)) or (not(r2 or r4)))
  		"orn r12, r1, r12;"					//	r12	<= not((not(((r0 and r3)) or (not(r2 or r4)))) or r1)
  		"and r11, r1, r0;"					//	r11	<= (r1 and r0)
  		"orr r11, r11, r5;"					//	r11	<= ((r1 and r0) or r5)
  		"and r11, r11, r2;"					//	r11	<= (((r1 and r0) or r5) and r2)
  		"orn r11, r11, r12;"				//	r11	<= not((((r1 and r0) or r5) and r2) or (not((not(((r0 and r3)) or (not(r2 or r4)))) or r1)))
  		/*		Sbox implementation assembly end	*/
  	);

  	asm(	/* shift columns */
  		"mov r0, r6;"
  		"mov r1, r7, ror #31;"
  		"mov r2, r8, ror #30;"
  		"mov r3, r9, ror #29;"
  		"mov r4, r10, ror #28;"
  		"mov r5, r11, ror #27;"
  		/* shift columns end */
  	);

  	asm(	/* mix columns*/
  		"eor r0, r0, r6, ror #31;" 			//here the mix columns for the r0 register is calculated
  		"eor r0, r0, r6, ror #27;"
  		"eor r0, r0, r6, ror #23;"
  		"eor r0, r0, r6, ror #17;"
  		"eor r0, r0, r6, ror #11;"
  		"eor r0, r0, r6, ror #6;"

  		"eor r1, r1, r7, ror #30;"			//mix columns for the r1 register is calculated
  		"eor r1, r1, r7, ror #26;"
  		"eor r1, r1, r7, ror #22;"
  		"eor r1, r1, r7, ror #16;"
  		"eor r1, r1, r7, ror #10;"
  		"eor r1, r1, r7, ror #5;"

  		"eor r2, r2, r8, ror #29;"			//mix columns for the r2 register is calculated
  		"eor r2, r2, r8, ror #25;"
  		"eor r2, r2, r8, ror #21;"
  		"eor r2, r2, r8, ror #15;"
  		"eor r2, r2, r8, ror #9;"
  		"eor r2, r2, r8, ror #4;"

  		"eor r3, r3, r9, ror #28;"			//mix columns for the r3 register is calculated
  		"eor r3, r3, r9, ror #24;"
  		"eor r3, r3, r9, ror #20;"
  		"eor r3, r3, r9, ror #14;"
  		"eor r3, r3, r9, ror #8;"
  		"eor r3, r3, r9, ror #3;"

  		"eor r4, r4, r10, ror #27;"			//mix columns for the r4 register is calculated
  		"eor r4, r4, r10, ror #23;"
  		"eor r4, r4, r10, ror #19;"
  		"eor r4, r4, r10, ror #13;"
  		"eor r4, r4, r10, ror #7;"
  		"eor r4, r4, r10, ror #2;"

  		"eor r5, r5, r11, ror #26;"			//mix columns for the r5 register is calculated
  		"eor r5, r5, r11, ror #22;"
  		"eor r5, r5, r11, ror #18;"
  		"eor r5, r5, r11, ror #12;"
  		"eor r5, r5, r11, ror #6;"
  		"eor r5, r5, r11, ror #1;"
  		/* mix columns end*/
  	);

  	asm(	/*		Round constants in bitslice representation		*/
  		/*		register from r6 to r12 haven't valid data erase them	*/
  		"mov 	r6, 0X963C;"				//move the round constant low part in bitslice representation	bit 0
  		"movt	r6, 0X7873;"				//move the round constant high part in bitslice representation  bit 0
  		"mov	r7, 0X9BB3;"				//move the round constant low part in bitslice representation   bit 1
  		"movt	r7, 0XC98A;"				//move the round constant high part in bitslice representation  bit 1
  		"mov	r8, 0XF8E7;"				//move the round constant low part in bitslice representation	bit 2
  		"movt	r8, 0X8006;"				//move the round constant high part in bitslice representation  bit 2
  		"mov	r9, 0XBBA0;"				//move the round constant low part in bitslice representation	bit 3
  		"movt	r9, 0X6F7C;"				//move the round constant high part in bitslice representation  bit 3
  		"mov	r10, 0X0A1C;"				//move the round constant low part in bitslice representation	bit 4
  		"movt	r10, 0X4DEF;"				//move the round constant high part in bitslice representation  bit 4
  		"mov	r11, 0XD9AE;"				//move the round constant low part in bitslice representation	bit 5
  		"movt   r11, 0X0785;"				//move the round constant high part in bitslice representation  bit 5
  /*		add round constant to the state i.e. blk i xor constant i		*/
  		"eor r0, r0, r6;"
  		"eor r1, r1, r7;"
  		"eor r2, r2, r8;"
  		"eor r3, r3, r9;"
  		"eor r4, r4, r10;"
  		"eor r5, r5, r11;"
  		"eor r12, r12;"
  	);
  	/*at this point the 5th round is done the results are in r0 - r5 then r6 - r12 can be clean*/

  ///////////// round  6 //////////////
  	asm(	/*	ARK	 the key must be in bitslice*/
  		"ldr r6, [sp, #144];"				//load bitslice key [6]  only bit "b_0"
  		"ldr r7, [sp, #148];"				//load bitslice key [6]  only bit "b_1"
  		"ldr r8, [sp, #152];"				//load bitslice key [6]  only bit "b_2"
  		"ldr r9, [sp, #156];"				//load bitslice key [6]  only bit "b_3"
  		"ldr r10, [sp, #160];"				//load bitslice key [6]  only bit "b_4"
  		"ldr r11, [sp, #164];"				//load bitslice key [6]  only bit "b_5"
  			/* XOR each register with the key position bit*/
  		"eor r0, r0, r6;"
  		"eor r1, r1, r7;"
  		"eor r2, r2, r8;"
  		"eor r3, r3, r9;"
  		"eor r4, r4, r10;"
  		"eor r5, r5, r11;"
  		/*EN of ARK*/
  	);

  	asm(	/*		Sbox implementation in assembly		*/
  		"and r9, r4, r2;"					//  r9  <= r2 and r4
  		"orn r9, r9, r5;"					//  r9  <= not((r2 and r4) or r5)
  		"and r9, r9, r3;"					//	r9  <= r3 and not((r2 and r4) or r5)
  		"and r10, r5, r4;"					//	r10 <= (r5 and r4)
  		"orn r11, r3, r0;"					//	r11 <= not(r3 or r0)
  		"orn r10, r10, r11;"				//	r10 <= not((r5 and r4) or (not(r3 or r0)))
  		"and r10, r1, r10;"					//	r10 <= (not((r5 and r4) or (not(r3 or r0)))) and (r1)
  		"orr r6, r10, r9;"					//	r6  <= (((not((r5 and r4) or (not(r3 or r0)))) and (r1)) or (r3 and not((r2 and r4) or r5)))

  		"and r9, r0, r2;"					//	r9  <= (r0 and r2)			r9 	overwrite
  		"orn r10, r2, r3;"					//	r10 <= not(r2 or r3)		r10 overwrite
  		"orn r9, r9, r10;"					//	r9	<= not((r0 and r0) or (not(r2 or r3)))
  		"and r9, r9, r5;"					//	r9	<= ((not((r0 and r0) or (not(r2 or r3)))) and r5)
  		"orr r10, r5, r4;"					//	r10 <= (r5 or r4)			r10 overwrite
  		"orn r10, r10, r3;"					//	r10 <= not((not(r5 or r4)) or r3)
  		"orn r9, r9, r10;"					//	r9 	<= not(((not((r0 and r0) or (not(r2 or r3)))) and r5) or (not((not(r5 or r4)) or r3)))
  		"orr r10, r0, r3;"					//	r10 <= (r0 or r3)			r10	overwrite
  		"orn r10, r10, r1;"					//	r10	<= not((r0 or r3) or r1)
  		"orn r7, r9, r10;"					//	r7	<= not((not(((not((r0 and r0) or (not(r2 or r3)))) and r5) or (not((not(r5 or r4)) or r3)))) or (not((r0 or r3) or r1)) )

  		"and r9, r1, r3;"					//	r9 	<= (r1 and r3)			r9	overwrite
  		"orn r10, r3, r4;"					//	r10 <= not(r3 or r4)		r10	overwrite
  		"orn r9, r9, r10;"					//	r9	<= not((not(r3 or r4)) or (r1 and r3))
  		"and r9, r0, r9;"					//	r9	<= ((not((not(r3 or r4)) or (r1 and r3))) and r0)
  		"orr r10, r3, r4;"					//	r10 <= (r3 or r4)			r10	overwrite
  		"orn r10, r10, r2;"					//	r10	<= not((r3 or r4) or r2)
  		"orn r9, r9, r10;"					//	r9	<= not(((not((not(r3 or r4)) or (r1 and r3))) and r0) or (not((r3 or r4) or r2)) )
  		"orr r10, r0, r2;"					//	r10	<= (r0 or r2)			r10	overwrite
  		"orr r10, r10, r5;"					//	r10 <= ((r0 or r2) or r5)
  		"orn r8, r9, r10;"					//	r8	<= not((not(((not((not(r3 or r4)) or (r1 and r3))) and r0) or (not((r3 or r4) or r2)))) or (((r0 or r2) or r5)))

  		"and r9, r0, r4;"					//	r9	<= (r0 and r4)			r9	overwrite
  		"orr r10, r0, r3;"					//	r10	<= (r0 or r3)			r10 overwrite
  		"orn r9, r9, r10;"					//	r9	<= not((r0 and r4) or (r0 or r3))
  		"and r9, r9, r2;"					//	r9	<= ((not((r0 and r4) or (r0 or r3))) and r2)
  		"and r10, r0, r5;"					//	r10 <= (r0 and r5)			r10	overwrite
  		"orn r10, r2, r10;"					//	r10	<= not((r0 and r5) or r2)
  		"orn r9, r9, r10;"					//	r9	<= not(((not((r0 and r4) or (r0 or r3))) and r2) or (not((r0 and r5) or r2)))
  		"and r10, r1, r3;"					//	r10 <= (r1 and r3)			r10 overwrite
  		"orn r10, r0, r10;"					//	r10	<= not((r1 and r3) or r0)
  		"orn r9, r9, r10;"					//	r9	<= not((not(((not((r0 and r4) or (r0 or r3))) and r2) or (not((r0 and r5) or r2)))) or (not((r1 and r3) or r0)))

  		"eor r12, r12, r12;" 		      	//	r12 <= 0's

  		"orr r10, r4, r2;"					//	r10	<= (r4 or r2)
  		"orr r11, r0, r1;"					//	r11 <= (r0 or r1)
  		"orn r10, r10, r11;"				//	r10	<= not((r4 or r2) or (r0 or r1))
  		"orn r10, r12, r10;"				//	r10	<= not(() or (not((r4 or r2) or (r0 or r1))))
  		"orn r11, r3, r0;"					//	r11	<= not( r3 or r0)		r11	overwrite
  		"orn r10, r10, r11;"				//	r10	<= not((not(() or (not((r4 or r2) or (r0 or r1))))) or (not( r3 or r0)))
  		"and r11, r4, r5;"					//	r11	<= (r4 and r5)			r11	overwrite
  		"orn r11, r0, r11;"					//	r11 <= not((r4 and r5) or r0)
  		"orn r10, r10, r11;"				//	r10 <= not((not((not(() or (not((r4 or r2) or (r0 or r1))))) or (not( r3 or r0)))) or (not((r4 and r5) or r0)))

  		"and r12, r0, r3;"					//  r12 <= (r0 and r3)			r12	overwrite
  		"orn r11, r2, r4;"					//	r11	<= not(r2 or r4)		r11	overwrite
  		"orn r12, r12, r11;"				//	r12	<= not(((r0 and r3)) or (not(r2 or r4)))
  		"orn r12, r1, r12;"					//	r12	<= not((not(((r0 and r3)) or (not(r2 or r4)))) or r1)
  		"and r11, r1, r0;"					//	r11	<= (r1 and r0)
  		"orr r11, r11, r5;"					//	r11	<= ((r1 and r0) or r5)
  		"and r11, r11, r2;"					//	r11	<= (((r1 and r0) or r5) and r2)
  		"orn r11, r11, r12;"				//	r11	<= not((((r1 and r0) or r5) and r2) or (not((not(((r0 and r3)) or (not(r2 or r4)))) or r1)))
  		/*		Sbox implementation assembly end	*/
  	);

  	asm(	/* shift columns */
  		"mov r0, r6;"
  		"mov r1, r7, ror #31;"
  		"mov r2, r8, ror #30;"
  		"mov r3, r9, ror #29;"
  		"mov r4, r10, ror #28;"
  		"mov r5, r11, ror #27;"
  		/* shift columns end */
  	);

  	asm(/*		Sbox implementation in assembly		*/
  		"and r9, r4, r2;"					//  r9  <= r2 and r4
  		"orn r9, r9, r5;"					//  r9  <= not((r2 and r4) or r5)
  		"and r9, r9, r3;"					//	r9  <= r3 and not((r2 and r4) or r5)
  		"and r10, r5, r4;"					//	r10 <= (r5 and r4)
  		"orn r11, r3, r0;"					//	r11 <= not(r3 or r0)
  		"orn r10, r10, r11;"				//	r10 <= not((r5 and r4) or (not(r3 or r0)))
  		"and r10, r1, r10;"					//	r10 <= (not((r5 and r4) or (not(r3 or r0)))) and (r1)
  		"orr r6, r10, r9;"					//	r6  <= (((not((r5 and r4) or (not(r3 or r0)))) and (r1)) or (r3 and not((r2 and r4) or r5)))

  		"and r9, r0, r2;"					//	r9  <= (r0 and r2)			r9 	overwrite
  		"orn r10, r2, r3;"					//	r10 <= not(r2 or r3)		r10 overwrite
  		"orn r9, r9, r10;"					//	r9	<= not((r0 and r0) or (not(r2 or r3)))
  		"and r9, r9, r5;"					//	r9	<= ((not((r0 and r0) or (not(r2 or r3)))) and r5)
  		"orr r10, r5, r4;"					//	r10 <= (r5 or r4)			r10 overwrite
  		"orn r10, r10, r3;"					//	r10 <= not((not(r5 or r4)) or r3)
  		"orn r9, r9, r10;"					//	r9 	<= not(((not((r0 and r0) or (not(r2 or r3)))) and r5) or (not((not(r5 or r4)) or r3)))
  		"orr r10, r0, r3;"					//	r10 <= (r0 or r3)			r10	overwrite
  		"orn r10, r10, r1;"					//	r10	<= not((r0 or r3) or r1)
  		"orn r7, r9, r10;"					//	r7	<= not((not(((not((r0 and r0) or (not(r2 or r3)))) and r5) or (not((not(r5 or r4)) or r3)))) or (not((r0 or r3) or r1)) )

  		"and r9, r1, r3;"					//	r9 	<= (r1 and r3)			r9	overwrite
  		"orn r10, r3, r4;"					//	r10 <= not(r3 or r4)		r10	overwrite
  		"orn r9, r9, r10;"					//	r9	<= not((not(r3 or r4)) or (r1 and r3))
  		"and r9, r0, r9;"					//	r9	<= ((not((not(r3 or r4)) or (r1 and r3))) and r0)
  		"orr r10, r3, r4;"					//	r10 <= (r3 or r4)			r10	overwrite
  		"orn r10, r10, r2;"					//	r10	<= not((r3 or r4) or r2)
  		"orn r9, r9, r10;"					//	r9	<= not(((not((not(r3 or r4)) or (r1 and r3))) and r0) or (not((r3 or r4) or r2)) )
  		"orr r10, r0, r2;"					//	r10	<= (r0 or r2)			r10	overwrite
  		"orr r10, r10, r5;"					//	r10 <= ((r0 or r2) or r5)
  		"orn r8, r9, r10;"					//	r8	<= not((not(((not((not(r3 or r4)) or (r1 and r3))) and r0) or (not((r3 or r4) or r2)))) or (((r0 or r2) or r5)))

  		"and r9, r0, r4;"					//	r9	<= (r0 and r4)			r9	overwrite
  		"orr r10, r0, r3;"					//	r10	<= (r0 or r3)			r10 overwrite
  		"orn r9, r9, r10;"					//	r9	<= not((r0 and r4) or (r0 or r3))
  		"and r9, r9, r2;"					//	r9	<= ((not((r0 and r4) or (r0 or r3))) and r2)
  		"and r10, r0, r5;"					//	r10 <= (r0 and r5)			r10	overwrite
  		"orn r10, r2, r10;"					//	r10	<= not((r0 and r5) or r2)
  		"orn r9, r9, r10;"					//	r9	<= not(((not((r0 and r4) or (r0 or r3))) and r2) or (not((r0 and r5) or r2)))
  		"and r10, r1, r3;"					//	r10 <= (r1 and r3)			r10 overwrite
  		"orn r10, r0, r10;"					//	r10	<= not((r1 and r3) or r0)
  		"orn r9, r9, r10;"					//	r9	<= not((not(((not((r0 and r4) or (r0 or r3))) and r2) or (not((r0 and r5) or r2)))) or (not((r1 and r3) or r0)))

  		"eor r12, r12, r12;" 		    	//	r12 <= 0's

  		"orr r10, r4, r2;"					//	r10	<= (r4 or r2)
  		"orr r11, r0, r1;"					//	r11 <= (r0 or r1)
  		"orn r10, r10, r11;"				//	r10	<= not((r4 or r2) or (r0 or r1))
  		"orn r10, r12, r10;"				//	r10	<= not(() or (not((r4 or r2) or (r0 or r1))))
  		"orn r11, r3, r0;"					//	r11	<= not( r3 or r0)		r11	overwrite
  		"orn r10, r10, r11;"				//	r10	<= not((not(() or (not((r4 or r2) or (r0 or r1))))) or (not( r3 or r0)))
  		"and r11, r4, r5;"					//	r11	<= (r4 and r5)			r11	overwrite
  		"orn r11, r0, r11;"					//	r11 <= not((r4 and r5) or r0)
  		"orn r10, r10, r11;"				//	r10 <= not((not((not(() or (not((r4 or r2) or (r0 or r1))))) or (not( r3 or r0)))) or (not((r4 and r5) or r0)))

  		"and r12, r0, r3;"					//  r12 <= (r0 and r3)			r12	overwrite
  		"orn r11, r2, r4;"					//	r11	<= not(r2 or r4)		r11	overwrite
  		"orn r12, r12, r11;"				//	r12	<= not(((r0 and r3)) or (not(r2 or r4)))
  		"orn r12, r1, r12;"					//	r12	<= not((not(((r0 and r3)) or (not(r2 or r4)))) or r1)
  		"and r11, r1, r0;"					//	r11	<= (r1 and r0)
  		"orr r11, r11, r5;"					//	r11	<= ((r1 and r0) or r5)
  		"and r11, r11, r2;"					//	r11	<= (((r1 and r0) or r5) and r2)
  		"orn r11, r11, r12;"				//	r11	<= not((((r1 and r0) or r5) and r2) or (not((not(((r0 and r3)) or (not(r2 or r4)))) or r1)))
  		/*		Sbox implementation assembly end	*/
  	);

  	asm(	/*		LAST KEY in bitslice representation		*/
  		/*		register from r6 to r12 haven't valid data erase them	*/
  		"ldr r0, [sp, #168];"				//load bitslice key [6]  only bit "b_0"
  		"ldr r1, [sp, #172];"				//load bitslice key [6]  only bit "b_1"
  		"ldr r2, [sp, #176];"				//load bitslice key [6]  only bit "b_2"
  		"ldr r3, [sp, #180];"				//load bitslice key [6]  only bit "b_3"
  		"ldr r4, [sp, #184];"				//load bitslice key [6]  only bit "b_4"
  		"ldr r5, [sp, #188];"				//load bitslice key [6]  only bit "b_5"
  		/*	LAST add round KEY to the state i.e. blk i xor constant i		*/
  		"eor r0, r0, r6;"
  		"eor r1, r1, r7;"
  		"eor r2, r2, r8;"
  		"eor r3, r3, r9;"
  		"eor r4, r4, r10;"
  		"eor r5, r5, r11;"
  		"eor r12, r12;"
  	);
  	/*at this point the 6th round is done the results are in r0 - r5 then r6 - r12 can be clean*/

  	stopE  = *ARM_CM_DWT_CYCCNT;
  	deltaE = stopE - startE;

  	//serial_out("Done! ", NULL, NULL, NULL, NULL, NULL, NULL, NULL);

  	serial_out("Bitslcie Clock cycles = ", NULL, NULL, NULL, NULL, NULL, NULL, &deltaB);
  	serial_out("Encryption Clock cycles = ", NULL, NULL, NULL, NULL, NULL, NULL, &deltaE);

  /* USER CODE END 2 */

  /* Infinite loop */
  while (1)
  {

  }
}

void SystemClock_Config(void)
{
  RCC_OscInitTypeDef RCC_OscInitStruct = {0};
  RCC_ClkInitTypeDef RCC_ClkInitStruct = {0};

  /** Configure the main internal regulator output voltage
  */
  if (HAL_PWREx_ControlVoltageScaling(PWR_REGULATOR_VOLTAGE_SCALE1) != HAL_OK)
  {
    Error_Handler();
  }
  /** Initializes the RCC Oscillators according to the specified parameters
  * in the RCC_OscInitTypeDef structure.
  */
  RCC_OscInitStruct.OscillatorType = RCC_OSCILLATORTYPE_MSI;
  RCC_OscInitStruct.MSIState = RCC_MSI_ON;
  RCC_OscInitStruct.MSICalibrationValue = 0;
  RCC_OscInitStruct.MSIClockRange = RCC_MSIRANGE_6;
  RCC_OscInitStruct.PLL.PLLState = RCC_PLL_ON;
  RCC_OscInitStruct.PLL.PLLSource = RCC_PLLSOURCE_MSI;
  RCC_OscInitStruct.PLL.PLLM = 1;
  RCC_OscInitStruct.PLL.PLLN = 71;
  RCC_OscInitStruct.PLL.PLLP = RCC_PLLP_DIV2;
  RCC_OscInitStruct.PLL.PLLQ = RCC_PLLQ_DIV2;
  RCC_OscInitStruct.PLL.PLLR = RCC_PLLR_DIV6;
  if (HAL_RCC_OscConfig(&RCC_OscInitStruct) != HAL_OK)
  {
    Error_Handler();
  }
  /** Initializes the CPU, AHB and APB buses clocks
  */
  RCC_ClkInitStruct.ClockType = RCC_CLOCKTYPE_HCLK|RCC_CLOCKTYPE_SYSCLK
                              |RCC_CLOCKTYPE_PCLK1|RCC_CLOCKTYPE_PCLK2;
  RCC_ClkInitStruct.SYSCLKSource = RCC_SYSCLKSOURCE_PLLCLK;
  RCC_ClkInitStruct.AHBCLKDivider = RCC_SYSCLK_DIV1;
  RCC_ClkInitStruct.APB1CLKDivider = RCC_HCLK_DIV2;
  RCC_ClkInitStruct.APB2CLKDivider = RCC_HCLK_DIV1;

  if (HAL_RCC_ClockConfig(&RCC_ClkInitStruct, FLASH_LATENCY_2) != HAL_OK)
  {
    Error_Handler();
  }
}

static void MX_LPUART1_UART_Init(void)
{

  hlpuart1.Instance = LPUART1;
  hlpuart1.Init.BaudRate = 115200;
  hlpuart1.Init.WordLength = UART_WORDLENGTH_8B;
  hlpuart1.Init.StopBits = UART_STOPBITS_1;
  hlpuart1.Init.Parity = UART_PARITY_NONE;
  hlpuart1.Init.Mode = UART_MODE_TX_RX;
  hlpuart1.Init.HwFlowCtl = UART_HWCONTROL_NONE;
  hlpuart1.Init.OneBitSampling = UART_ONE_BIT_SAMPLE_DISABLE;
  hlpuart1.AdvancedInit.AdvFeatureInit = UART_ADVFEATURE_NO_INIT;
  if (HAL_UART_Init(&hlpuart1) != HAL_OK)
  {
    Error_Handler();
  }

}

static void MX_GPIO_Init(void)
{
  GPIO_InitTypeDef GPIO_InitStruct = {0};

  /* GPIO Ports Clock Enable */
  __HAL_RCC_GPIOC_CLK_ENABLE();
  __HAL_RCC_GPIOH_CLK_ENABLE();
  __HAL_RCC_GPIOB_CLK_ENABLE();
  __HAL_RCC_GPIOG_CLK_ENABLE();
  HAL_PWREx_EnableVddIO2();
  __HAL_RCC_GPIOA_CLK_ENABLE();

  /*Configure GPIO pin Output Level */
  HAL_GPIO_WritePin(GPIOB, LD3_Pin|LD2_Pin, GPIO_PIN_RESET);

  /*Configure GPIO pin Output Level */
  HAL_GPIO_WritePin(USB_PowerSwitchOn_GPIO_Port, USB_PowerSwitchOn_Pin, GPIO_PIN_RESET);

  /*Configure GPIO pin : B1_Pin */
  GPIO_InitStruct.Pin = B1_Pin;
  GPIO_InitStruct.Mode = GPIO_MODE_IT_RISING;
  GPIO_InitStruct.Pull = GPIO_NOPULL;
  HAL_GPIO_Init(B1_GPIO_Port, &GPIO_InitStruct);

  /*Configure GPIO pins : LD3_Pin LD2_Pin */
  GPIO_InitStruct.Pin = LD3_Pin|LD2_Pin;
  GPIO_InitStruct.Mode = GPIO_MODE_OUTPUT_PP;
  GPIO_InitStruct.Pull = GPIO_NOPULL;
  GPIO_InitStruct.Speed = GPIO_SPEED_FREQ_LOW;
  HAL_GPIO_Init(GPIOB, &GPIO_InitStruct);

  /*Configure GPIO pin : USB_OverCurrent_Pin */
  GPIO_InitStruct.Pin = USB_OverCurrent_Pin;
  GPIO_InitStruct.Mode = GPIO_MODE_INPUT;
  GPIO_InitStruct.Pull = GPIO_NOPULL;
  HAL_GPIO_Init(USB_OverCurrent_GPIO_Port, &GPIO_InitStruct);

  /*Configure GPIO pin : USB_PowerSwitchOn_Pin */
  GPIO_InitStruct.Pin = USB_PowerSwitchOn_Pin;
  GPIO_InitStruct.Mode = GPIO_MODE_OUTPUT_PP;
  GPIO_InitStruct.Pull = GPIO_NOPULL;
  GPIO_InitStruct.Speed = GPIO_SPEED_FREQ_LOW;
  HAL_GPIO_Init(USB_PowerSwitchOn_GPIO_Port, &GPIO_InitStruct);

  /*Configure GPIO pins : USB_SOF_Pin USB_ID_Pin USB_DM_Pin USB_DP_Pin */
  GPIO_InitStruct.Pin = USB_SOF_Pin|USB_ID_Pin|USB_DM_Pin|USB_DP_Pin;
  GPIO_InitStruct.Mode = GPIO_MODE_AF_PP;
  GPIO_InitStruct.Pull = GPIO_NOPULL;
  GPIO_InitStruct.Speed = GPIO_SPEED_FREQ_VERY_HIGH;
  GPIO_InitStruct.Alternate = GPIO_AF10_OTG_FS;
  HAL_GPIO_Init(GPIOA, &GPIO_InitStruct);

}

/* USER CODE BEGIN 4 */
void serial_out(char *label, uint8_t *dat0, uint8_t *dat1, uint8_t *dat2, uint8_t *dat3, uint8_t *dat4, uint8_t *dat5, int *i){

	uint16_t sz = 0;
	char m[MAX_BUFF];

	if((label != NULL) && (dat0 != NULL) && (dat1 != NULL) && (dat2 != NULL) && (dat3 != NULL) && (dat4 != NULL) && (dat5 != NULL) && (i == NULL)){
		sprintf(m, "%s %.2X%.2X%.2X%.2X %.2X%.2X%.2X%.2X %.2X%.2X%.2X%.2X %.2X%.2X%.2X%.2X %.2X%.2X%.2X%.2X %.2X%.2X%.2X%.2X \r\n",
		label, dat0[3], dat0[2], dat0[1], dat0[0],
			   dat1[3], dat1[2], dat1[1], dat1[0],
			   dat2[3], dat2[2], dat2[1], dat2[0],
			   dat3[3], dat3[2], dat3[1], dat3[0],
			   dat4[3], dat4[2], dat4[1], dat4[0],
			   dat5[3], dat5[2], dat5[1], dat5[0] );
	}

	if((label != NULL) && (i != NULL)){    // print string and integer //&& (dat0 = NULL) && (dat1 = NULL) && (dat2 = NULL) && (dat3 = NULL) && (dat4 = NULL) && (dat5 = NULL) && (i != NULL)){    // print string and integer
		sprintf(m, "%s %i \r\n", label, *i);
	}

	if((label != NULL) && (dat0 == NULL) && (dat1 == NULL) && (dat2 == NULL) && (dat3 == NULL) && (dat4 == NULL) && (dat5 == NULL) && (i == NULL)){    // print the string label
		sprintf(m, "%s \r\n", label);
	}

	sz = 0;
	do{
		sz++;
	}while(m[sz]!='\0');

	HAL_UART_Transmit(&hlpuart1, (uint8_t *)m, sz, HAL_MAX_DELAY);
}
/* USER CODE END 4 */

void Error_Handler(void)
{
  __disable_irq();
  while (1)
  {
  }
}

/************************ (C) COPYRIGHT STMicroelectronics *****END OF FILE****/
